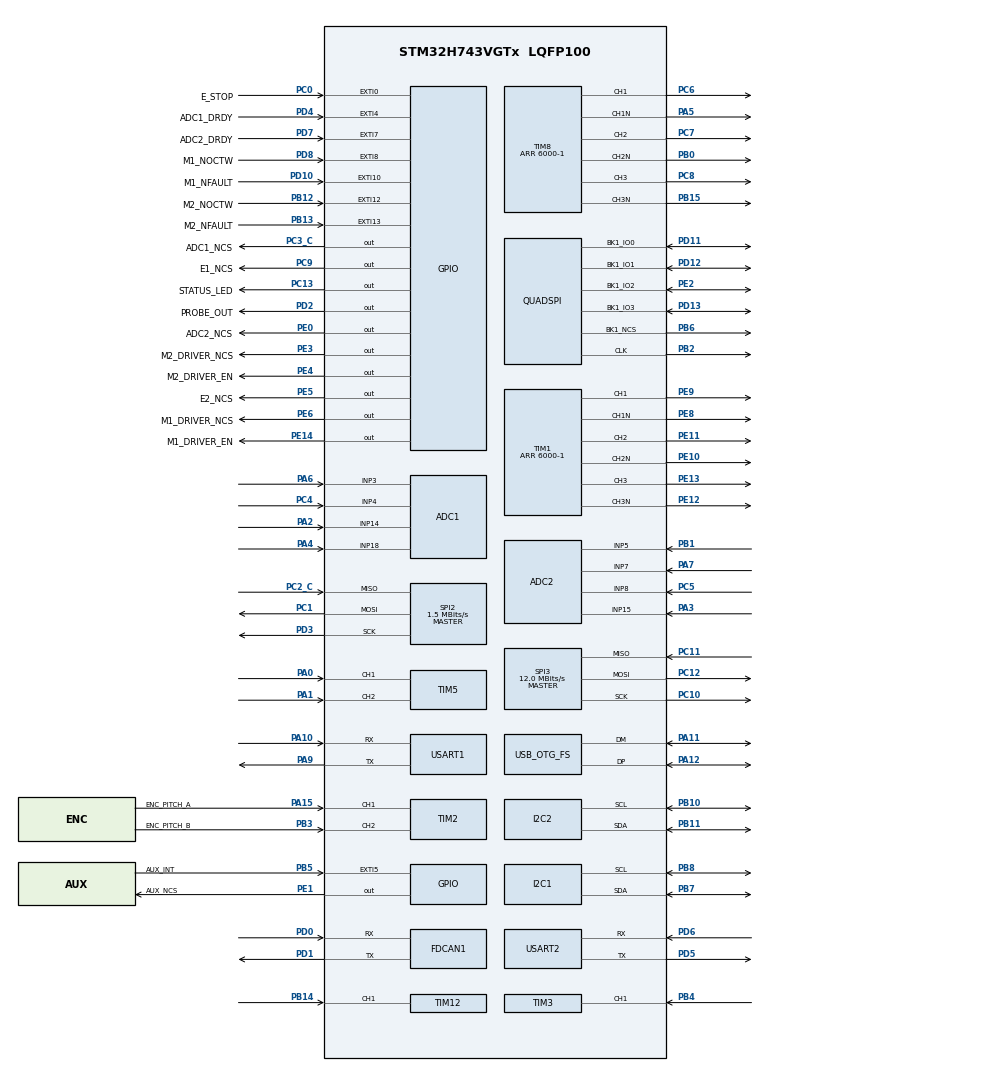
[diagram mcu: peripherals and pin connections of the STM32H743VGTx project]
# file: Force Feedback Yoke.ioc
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ADC1.AWD1HighThreshold=(65535-5000)*8
ADC1.AWD1ITMode=ENABLE
ADC1.AWD1LowThreshold=10000*8
ADC1.EOCSelection=ADC_EOC_SEQ_CONV
ADC1.EnableAnalogWatchDog1=true
ADC1.EnableInjectedConversion=ENABLE
ADC1.EnableInjectedOversampling=ENABLE
ADC1.EnableRegularConversion=DISABLE
ADC1.ExternalTrigInjecConv=ADC_EXTERNALTRIGINJEC_T8_TRGO
ADC1.InjNumberOfConversion=4
ADC1.InjOversamplingRatio=8
ADC1.InjOversamplingRightShift=ADC_RIGHTBITSHIFT_3
ADC1.InjectedChannel-10\#ChannelInjectedConversion=ADC_CHANNEL_18
ADC1.InjectedChannel-11\#ChannelInjectedConversion=ADC_CHANNEL_14
ADC1.InjectedChannel-12\#ChannelInjectedConversion=ADC_CHANNEL_4
ADC1.InjectedChannel-9\#ChannelInjectedConversion=ADC_CHANNEL_3
ADC1.InjectedOffsetNumber-10\#ChannelInjectedConversion=ADC_OFFSET_NONE
ADC1.InjectedOffsetNumber-11\#ChannelInjectedConversion=ADC_OFFSET_NONE
ADC1.InjectedOffsetNumber-12\#ChannelInjectedConversion=ADC_OFFSET_NONE
ADC1.InjectedOffsetNumber-9\#ChannelInjectedConversion=ADC_OFFSET_NONE
ADC1.InjectedOffsetSaturation-10\#ChannelInjectedConversion=DISABLE
ADC1.InjectedOffsetSaturation-11\#ChannelInjectedConversion=DISABLE
ADC1.InjectedOffsetSaturation-12\#ChannelInjectedConversion=DISABLE
ADC1.InjectedOffsetSaturation-9\#ChannelInjectedConversion=DISABLE
ADC1.InjectedOffsetSignedSaturation-10\#ChannelInjectedConversion=DISABLE
ADC1.InjectedOffsetSignedSaturation-11\#ChannelInjectedConversion=DISABLE
ADC1.InjectedOffsetSignedSaturation-12\#ChannelInjectedConversion=DISABLE
ADC1.InjectedOffsetSignedSaturation-9\#ChannelInjectedConversion=DISABLE
ADC1.InjectedRank-10\#ChannelInjectedConversion=2
ADC1.InjectedRank-11\#ChannelInjectedConversion=3
ADC1.InjectedRank-12\#ChannelInjectedConversion=4
ADC1.InjectedRank-9\#ChannelInjectedConversion=1
ADC1.InjectedSamplingTime-10\#ChannelInjectedConversion=ADC_SAMPLETIME_32CYCLES_5
ADC1.InjectedSamplingTime-11\#ChannelInjectedConversion=ADC_SAMPLETIME_32CYCLES_5
ADC1.InjectedSamplingTime-12\#ChannelInjectedConversion=ADC_SAMPLETIME_32CYCLES_5
ADC1.InjectedSamplingTime-9\#ChannelInjectedConversion=ADC_SAMPLETIME_32CYCLES_5
ADC1.OversamplingMode=DISABLE
ADC1.WatchdogMode=ADC_ANALOGWATCHDOG_ALL_INJEC
ADC1.injectedQueueMode=DISABLE
ADC1.master=1
ADC2.AWD1HighThreshold=(65535-5000)*8
ADC2.AWD1ITMode=ENABLE
ADC2.AWD1LowThreshold=10000*8
ADC2.ClockPrescaler=ADC_CLOCK_ASYNC_DIV1
ADC2.EOCSelection=ADC_EOC_SEQ_CONV
ADC2.EnableAnalogWatchDog1=true
ADC2.EnableAnalogWatchDog2=false
ADC2.EnableAnalogWatchDog3=false
ADC2.EnableInjectedConversion=ENABLE
ADC2.EnableInjectedOversampling=ENABLE
ADC2.EnableRegularConversion=DISABLE
ADC2.ExternalTrigInjecConv=ADC_EXTERNALTRIGINJEC_T1_TRGO
ADC2.InjNumberOfConversion=4
ADC2.InjOversamplingRatio=8
ADC2.InjOversamplingRightShift=ADC_RIGHTBITSHIFT_3
ADC2.InjectedChannel-13\#ChannelInjectedConversion=ADC_CHANNEL_7
ADC2.InjectedChannel-14\#ChannelInjectedConversion=ADC_CHANNEL_8
ADC2.InjectedChannel-15\#ChannelInjectedConversion=ADC_CHANNEL_5
ADC2.InjectedChannel-16\#ChannelInjectedConversion=ADC_CHANNEL_15
ADC2.InjectedOffsetNumber-13\#ChannelInjectedConversion=ADC_OFFSET_NONE
ADC2.InjectedOffsetNumber-14\#ChannelInjectedConversion=ADC_OFFSET_NONE
ADC2.InjectedOffsetNumber-15\#ChannelInjectedConversion=ADC_OFFSET_NONE
ADC2.InjectedOffsetNumber-16\#ChannelInjectedConversion=ADC_OFFSET_NONE
ADC2.InjectedOffsetSaturation-13\#ChannelInjectedConversion=DISABLE
ADC2.InjectedOffsetSaturation-14\#ChannelInjectedConversion=DISABLE
ADC2.InjectedOffsetSaturation-15\#ChannelInjectedConversion=DISABLE
ADC2.InjectedOffsetSaturation-16\#ChannelInjectedConversion=DISABLE
ADC2.InjectedOffsetSignedSaturation-13\#ChannelInjectedConversion=DISABLE
ADC2.InjectedOffsetSignedSaturation-14\#ChannelInjectedConversion=DISABLE
ADC2.InjectedOffsetSignedSaturation-15\#ChannelInjectedConversion=DISABLE
ADC2.InjectedOffsetSignedSaturation-16\#ChannelInjectedConversion=DISABLE
ADC2.InjectedRank-13\#ChannelInjectedConversion=1
ADC2.InjectedRank-14\#ChannelInjectedConversion=2
ADC2.InjectedRank-15\#ChannelInjectedConversion=3
ADC2.InjectedRank-16\#ChannelInjectedConversion=4
ADC2.InjectedSamplingTime-13\#ChannelInjectedConversion=ADC_SAMPLETIME_32CYCLES_5
ADC2.InjectedSamplingTime-14\#ChannelInjectedConversion=ADC_SAMPLETIME_32CYCLES_5
ADC2.InjectedSamplingTime-15\#ChannelInjectedConversion=ADC_SAMPLETIME_32CYCLES_5
ADC2.InjectedSamplingTime-16\#ChannelInjectedConversion=ADC_SAMPLETIME_32CYCLES_5
ADC2.Overrun=ADC_OVR_DATA_PRESERVED
ADC2.OversamplingMode=ENABLE
ADC2.Ratio=1
ADC2.WatchdogMode=ADC_ANALOGWATCHDOG_ALL_INJEC
ADC2.injectedQueueMode=DISABLE
CORTEX_M7.CPU_DCache=Disabled
CORTEX_M7.CPU_ICache=Enabled
CORTEX_M7.default_mode_Activation=1
CRC.CRCLength=CRC_POLYLENGTH_8B
CRC.DefaultInitValueUse=DEFAULT_INIT_VALUE_DISABLE
CRC.DefaultPolynomialUse=DEFAULT_POLYNOMIAL_DISABLE
Dma.Request0=USART2_RX
Dma.Request1=USART2_TX
Dma.Request10=TIM5_CH1
Dma.Request11=TIM5_CH2
Dma.Request2=SPI2_RX
Dma.Request3=SPI2_TX
Dma.Request4=USART1_RX
Dma.Request5=USART1_TX
Dma.Request6=SPI3_TX
Dma.Request7=SPI3_RX
Dma.Request8=TIM2_CH1
Dma.Request9=TIM2_CH2
Dma.SPI2_RX.2.Direction=DMA_PERIPH_TO_MEMORY
Dma.SPI2_RX.2.EventEnable=DISABLE
Dma.SPI2_RX.2.FIFOMode=DMA_FIFOMODE_DISABLE
Dma.SPI2_RX.2.Instance=DMA1_Stream0
Dma.SPI2_RX.2.MemDataAlignment=DMA_MDATAALIGN_BYTE
Dma.SPI2_RX.2.MemInc=DMA_MINC_ENABLE
Dma.SPI2_RX.2.Mode=DMA_NORMAL
Dma.SPI2_RX.2.PeriphDataAlignment=DMA_PDATAALIGN_BYTE
Dma.SPI2_RX.2.PeriphInc=DMA_PINC_DISABLE
Dma.SPI2_RX.2.Polarity=HAL_DMAMUX_REQ_GEN_RISING
Dma.SPI2_RX.2.Priority=DMA_PRIORITY_MEDIUM
Dma.SPI2_RX.2.RequestNumber=1
Dma.SPI2_RX.2.SignalID=NONE
Dma.SPI2_RX.2.SyncEnable=DISABLE
Dma.SPI2_RX.2.SyncPolarity=HAL_DMAMUX_SYNC_NO_EVENT
Dma.SPI2_RX.2.SyncRequestNumber=1
Dma.SPI2_RX.2.SyncSignalID=NONE
Dma.SPI2_TX.3.Direction=DMA_MEMORY_TO_PERIPH
Dma.SPI2_TX.3.EventEnable=DISABLE
Dma.SPI2_TX.3.FIFOMode=DMA_FIFOMODE_DISABLE
Dma.SPI2_TX.3.Instance=DMA1_Stream1
Dma.SPI2_TX.3.MemDataAlignment=DMA_MDATAALIGN_BYTE
Dma.SPI2_TX.3.MemInc=DMA_MINC_ENABLE
Dma.SPI2_TX.3.Mode=DMA_NORMAL
Dma.SPI2_TX.3.PeriphDataAlignment=DMA_PDATAALIGN_BYTE
Dma.SPI2_TX.3.PeriphInc=DMA_PINC_DISABLE
Dma.SPI2_TX.3.Polarity=HAL_DMAMUX_REQ_GEN_RISING
Dma.SPI2_TX.3.Priority=DMA_PRIORITY_MEDIUM
Dma.SPI2_TX.3.RequestNumber=1
Dma.SPI2_TX.3.SignalID=NONE
Dma.SPI2_TX.3.SyncEnable=DISABLE
Dma.SPI2_TX.3.SyncPolarity=HAL_DMAMUX_SYNC_NO_EVENT
Dma.SPI2_TX.3.SyncRequestNumber=1
Dma.SPI2_TX.3.SyncSignalID=NONE
Dma.SPI3_RX.7.Direction=DMA_PERIPH_TO_MEMORY
Dma.SPI3_RX.7.EventEnable=DISABLE
Dma.SPI3_RX.7.FIFOMode=DMA_FIFOMODE_DISABLE
Dma.SPI3_RX.7.Instance=DMA1_Stream7
Dma.SPI3_RX.7.MemDataAlignment=DMA_MDATAALIGN_BYTE
Dma.SPI3_RX.7.MemInc=DMA_MINC_ENABLE
Dma.SPI3_RX.7.Mode=DMA_NORMAL
Dma.SPI3_RX.7.PeriphDataAlignment=DMA_PDATAALIGN_BYTE
Dma.SPI3_RX.7.PeriphInc=DMA_PINC_DISABLE
Dma.SPI3_RX.7.Polarity=HAL_DMAMUX_REQ_GEN_RISING
Dma.SPI3_RX.7.Priority=DMA_PRIORITY_HIGH
Dma.SPI3_RX.7.RequestNumber=1
Dma.SPI3_RX.7.SignalID=NONE
Dma.SPI3_RX.7.SyncEnable=DISABLE
Dma.SPI3_RX.7.SyncPolarity=HAL_DMAMUX_SYNC_NO_EVENT
Dma.SPI3_RX.7.SyncRequestNumber=1
Dma.SPI3_RX.7.SyncSignalID=NONE
Dma.SPI3_TX.6.Direction=DMA_MEMORY_TO_PERIPH
Dma.SPI3_TX.6.EventEnable=DISABLE
Dma.SPI3_TX.6.FIFOMode=DMA_FIFOMODE_DISABLE
Dma.SPI3_TX.6.Instance=DMA1_Stream6
Dma.SPI3_TX.6.MemDataAlignment=DMA_MDATAALIGN_BYTE
Dma.SPI3_TX.6.MemInc=DMA_MINC_ENABLE
Dma.SPI3_TX.6.Mode=DMA_NORMAL
Dma.SPI3_TX.6.PeriphDataAlignment=DMA_PDATAALIGN_BYTE
Dma.SPI3_TX.6.PeriphInc=DMA_PINC_DISABLE
Dma.SPI3_TX.6.Polarity=HAL_DMAMUX_REQ_GEN_RISING
Dma.SPI3_TX.6.Priority=DMA_PRIORITY_HIGH
Dma.SPI3_TX.6.RequestNumber=1
Dma.SPI3_TX.6.SignalID=NONE
Dma.SPI3_TX.6.SyncEnable=DISABLE
Dma.SPI3_TX.6.SyncPolarity=HAL_DMAMUX_SYNC_NO_EVENT
Dma.SPI3_TX.6.SyncRequestNumber=1
Dma.SPI3_TX.6.SyncSignalID=NONE
Dma.TIM2_CH1.8.Direction=DMA_PERIPH_TO_MEMORY
Dma.TIM2_CH1.8.EventEnable=DISABLE
Dma.TIM2_CH1.8.FIFOMode=DMA_FIFOMODE_DISABLE
Dma.TIM2_CH1.8.Instance=DMA2_Stream0
Dma.TIM2_CH1.8.MemDataAlignment=DMA_MDATAALIGN_WORD
Dma.TIM2_CH1.8.MemInc=DMA_MINC_ENABLE
Dma.TIM2_CH1.8.Mode=DMA_CIRCULAR
Dma.TIM2_CH1.8.PeriphDataAlignment=DMA_PDATAALIGN_WORD
Dma.TIM2_CH1.8.PeriphInc=DMA_PINC_DISABLE
Dma.TIM2_CH1.8.Polarity=HAL_DMAMUX_REQ_GEN_RISING
Dma.TIM2_CH1.8.Priority=DMA_PRIORITY_MEDIUM
Dma.TIM2_CH1.8.RequestNumber=1
Dma.TIM2_CH1.8.SignalID=NONE
Dma.TIM2_CH1.8.SyncEnable=DISABLE
Dma.TIM2_CH1.8.SyncPolarity=HAL_DMAMUX_SYNC_NO_EVENT
Dma.TIM2_CH1.8.SyncRequestNumber=1
Dma.TIM2_CH1.8.SyncSignalID=NONE
Dma.TIM2_CH2.9.Direction=DMA_PERIPH_TO_MEMORY
Dma.TIM2_CH2.9.EventEnable=DISABLE
Dma.TIM2_CH2.9.FIFOMode=DMA_FIFOMODE_DISABLE
Dma.TIM2_CH2.9.Instance=DMA2_Stream1
Dma.TIM2_CH2.9.MemDataAlignment=DMA_MDATAALIGN_WORD
Dma.TIM2_CH2.9.MemInc=DMA_MINC_ENABLE
Dma.TIM2_CH2.9.Mode=DMA_CIRCULAR
Dma.TIM2_CH2.9.PeriphDataAlignment=DMA_PDATAALIGN_WORD
Dma.TIM2_CH2.9.PeriphInc=DMA_PINC_DISABLE
Dma.TIM2_CH2.9.Polarity=HAL_DMAMUX_REQ_GEN_RISING
Dma.TIM2_CH2.9.Priority=DMA_PRIORITY_MEDIUM
Dma.TIM2_CH2.9.RequestNumber=1
Dma.TIM2_CH2.9.SignalID=NONE
Dma.TIM2_CH2.9.SyncEnable=DISABLE
Dma.TIM2_CH2.9.SyncPolarity=HAL_DMAMUX_SYNC_NO_EVENT
Dma.TIM2_CH2.9.SyncRequestNumber=1
Dma.TIM2_CH2.9.SyncSignalID=NONE
Dma.TIM5_CH1.10.Direction=DMA_PERIPH_TO_MEMORY
Dma.TIM5_CH1.10.EventEnable=DISABLE
Dma.TIM5_CH1.10.FIFOMode=DMA_FIFOMODE_DISABLE
Dma.TIM5_CH1.10.Instance=DMA2_Stream2
Dma.TIM5_CH1.10.MemDataAlignment=DMA_MDATAALIGN_WORD
Dma.TIM5_CH1.10.MemInc=DMA_MINC_ENABLE
Dma.TIM5_CH1.10.Mode=DMA_NORMAL
Dma.TIM5_CH1.10.PeriphDataAlignment=DMA_PDATAALIGN_WORD
Dma.TIM5_CH1.10.PeriphInc=DMA_PINC_DISABLE
Dma.TIM5_CH1.10.Polarity=HAL_DMAMUX_REQ_GEN_RISING
Dma.TIM5_CH1.10.Priority=DMA_PRIORITY_MEDIUM
Dma.TIM5_CH1.10.RequestNumber=1
Dma.TIM5_CH1.10.SignalID=NONE
Dma.TIM5_CH1.10.SyncEnable=DISABLE
Dma.TIM5_CH1.10.SyncPolarity=HAL_DMAMUX_SYNC_NO_EVENT
Dma.TIM5_CH1.10.SyncRequestNumber=1
Dma.TIM5_CH1.10.SyncSignalID=NONE
Dma.TIM5_CH2.11.Direction=DMA_PERIPH_TO_MEMORY
Dma.TIM5_CH2.11.EventEnable=DISABLE
Dma.TIM5_CH2.11.FIFOMode=DMA_FIFOMODE_DISABLE
Dma.TIM5_CH2.11.Instance=DMA2_Stream3
Dma.TIM5_CH2.11.MemDataAlignment=DMA_MDATAALIGN_WORD
Dma.TIM5_CH2.11.MemInc=DMA_MINC_ENABLE
Dma.TIM5_CH2.11.Mode=DMA_NORMAL
Dma.TIM5_CH2.11.PeriphDataAlignment=DMA_PDATAALIGN_WORD
Dma.TIM5_CH2.11.PeriphInc=DMA_PINC_DISABLE
Dma.TIM5_CH2.11.Polarity=HAL_DMAMUX_REQ_GEN_RISING
Dma.TIM5_CH2.11.Priority=DMA_PRIORITY_MEDIUM
Dma.TIM5_CH2.11.RequestNumber=1
Dma.TIM5_CH2.11.SignalID=NONE
Dma.TIM5_CH2.11.SyncEnable=DISABLE
Dma.TIM5_CH2.11.SyncPolarity=HAL_DMAMUX_SYNC_NO_EVENT
Dma.TIM5_CH2.11.SyncRequestNumber=1
Dma.TIM5_CH2.11.SyncSignalID=NONE
Dma.USART1_RX.4.Direction=DMA_PERIPH_TO_MEMORY
Dma.USART1_RX.4.EventEnable=DISABLE
Dma.USART1_RX.4.FIFOMode=DMA_FIFOMODE_DISABLE
Dma.USART1_RX.4.Instance=DMA1_Stream4
Dma.USART1_RX.4.MemDataAlignment=DMA_MDATAALIGN_BYTE
Dma.USART1_RX.4.MemInc=DMA_MINC_ENABLE
Dma.USART1_RX.4.Mode=DMA_NORMAL
Dma.USART1_RX.4.PeriphDataAlignment=DMA_PDATAALIGN_BYTE
Dma.USART1_RX.4.PeriphInc=DMA_PINC_DISABLE
Dma.USART1_RX.4.Polarity=HAL_DMAMUX_REQ_GEN_RISING
Dma.USART1_RX.4.Priority=DMA_PRIORITY_LOW
Dma.USART1_RX.4.RequestNumber=1
Dma.USART1_RX.4.SignalID=NONE
Dma.USART1_RX.4.SyncEnable=DISABLE
Dma.USART1_RX.4.SyncPolarity=HAL_DMAMUX_SYNC_NO_EVENT
Dma.USART1_RX.4.SyncRequestNumber=1
Dma.USART1_RX.4.SyncSignalID=NONE
Dma.USART1_TX.5.Direction=DMA_MEMORY_TO_PERIPH
Dma.USART1_TX.5.EventEnable=DISABLE
Dma.USART1_TX.5.FIFOMode=DMA_FIFOMODE_DISABLE
Dma.USART1_TX.5.Instance=DMA1_Stream5
Dma.USART1_TX.5.MemDataAlignment=DMA_MDATAALIGN_BYTE
Dma.USART1_TX.5.MemInc=DMA_MINC_ENABLE
Dma.USART1_TX.5.Mode=DMA_NORMAL
Dma.USART1_TX.5.PeriphDataAlignment=DMA_PDATAALIGN_BYTE
Dma.USART1_TX.5.PeriphInc=DMA_PINC_DISABLE
Dma.USART1_TX.5.Polarity=HAL_DMAMUX_REQ_GEN_RISING
Dma.USART1_TX.5.Priority=DMA_PRIORITY_LOW
Dma.USART1_TX.5.RequestNumber=1
Dma.USART1_TX.5.SignalID=NONE
Dma.USART1_TX.5.SyncEnable=DISABLE
Dma.USART1_TX.5.SyncPolarity=HAL_DMAMUX_SYNC_NO_EVENT
Dma.USART1_TX.5.SyncRequestNumber=1
Dma.USART1_TX.5.SyncSignalID=NONE
Dma.USART2_RX.0.Direction=DMA_PERIPH_TO_MEMORY
Dma.USART2_RX.0.EventEnable=DISABLE
Dma.USART2_RX.0.FIFOMode=DMA_FIFOMODE_DISABLE
Dma.USART2_RX.0.Instance=DMA1_Stream2
Dma.USART2_RX.0.MemDataAlignment=DMA_MDATAALIGN_BYTE
Dma.USART2_RX.0.MemInc=DMA_MINC_ENABLE
Dma.USART2_RX.0.Mode=DMA_NORMAL
Dma.USART2_RX.0.PeriphDataAlignment=DMA_PDATAALIGN_BYTE
Dma.USART2_RX.0.PeriphInc=DMA_PINC_DISABLE
Dma.USART2_RX.0.Polarity=HAL_DMAMUX_REQ_GEN_RISING
Dma.USART2_RX.0.Priority=DMA_PRIORITY_LOW
Dma.USART2_RX.0.RequestNumber=1
Dma.USART2_RX.0.SignalID=NONE
Dma.USART2_RX.0.SyncEnable=DISABLE
Dma.USART2_RX.0.SyncPolarity=HAL_DMAMUX_SYNC_NO_EVENT
Dma.USART2_RX.0.SyncRequestNumber=1
Dma.USART2_RX.0.SyncSignalID=NONE
Dma.USART2_TX.1.Direction=DMA_MEMORY_TO_PERIPH
Dma.USART2_TX.1.EventEnable=DISABLE
Dma.USART2_TX.1.FIFOMode=DMA_FIFOMODE_DISABLE
Dma.USART2_TX.1.Instance=DMA1_Stream3
Dma.USART2_TX.1.MemDataAlignment=DMA_MDATAALIGN_BYTE
Dma.USART2_TX.1.MemInc=DMA_MINC_ENABLE
Dma.USART2_TX.1.Mode=DMA_NORMAL
Dma.USART2_TX.1.PeriphDataAlignment=DMA_PDATAALIGN_BYTE
Dma.USART2_TX.1.PeriphInc=DMA_PINC_DISABLE
Dma.USART2_TX.1.Polarity=HAL_DMAMUX_REQ_GEN_RISING
Dma.USART2_TX.1.Priority=DMA_PRIORITY_LOW
Dma.USART2_TX.1.RequestNumber=1
Dma.USART2_TX.1.SignalID=NONE
Dma.USART2_TX.1.SyncEnable=DISABLE
Dma.USART2_TX.1.SyncPolarity=HAL_DMAMUX_SYNC_NO_EVENT
Dma.USART2_TX.1.SyncRequestNumber=1
Dma.USART2_TX.1.SyncSignalID=NONE
FDCAN1.CalculateBaudRateNominal=1666666
FDCAN1.CalculateTimeBitNominal=600
FDCAN1.CalculateTimeQuantumNominal=200.0
I2C1.Timing=0x307075B1
I2C2.CustomTiming=Disabled
I2C2.Timing=0x307075B1
Mcu.Family=STM32H7
Mcu.Name=STM32H743VGTx
Mcu.Package=LQFP100
NVIC.ADC_IRQn=true\:1\:0\:true\:false\:true\:true\:true\:true
NVIC.DMA1_Stream0_IRQn=true\:1\:0\:true\:false\:true\:false\:true\:true
NVIC.DMA1_Stream1_IRQn=true\:1\:0\:true\:false\:true\:false\:true\:true
NVIC.DMA1_Stream2_IRQn=true\:3\:0\:true\:false\:true\:false\:true\:true
NVIC.DMA1_Stream3_IRQn=true\:3\:0\:true\:false\:true\:false\:true\:true
NVIC.DMA1_Stream4_IRQn=true\:3\:0\:true\:false\:true\:false\:true\:true
NVIC.DMA1_Stream5_IRQn=true\:3\:0\:true\:false\:true\:false\:true\:true
NVIC.DMA1_Stream6_IRQn=true\:0\:0\:false\:false\:true\:false\:true\:true
NVIC.DMA1_Stream7_IRQn=true\:0\:0\:false\:false\:true\:false\:true\:true
NVIC.DMA2_Stream0_IRQn=true\:0\:0\:false\:false\:true\:false\:true\:true
NVIC.DMA2_Stream1_IRQn=true\:0\:0\:false\:false\:true\:false\:true\:true
NVIC.DMA2_Stream2_IRQn=true\:0\:0\:false\:false\:true\:false\:true\:true
NVIC.DMA2_Stream3_IRQn=true\:0\:0\:false\:false\:true\:false\:true\:true
NVIC.EXTI0_IRQn=true\:0\:0\:false\:false\:true\:true\:true\:true
NVIC.EXTI4_IRQn=true\:1\:0\:true\:false\:true\:true\:true\:true
NVIC.OTG_FS_IRQn=true\:0\:0\:false\:false\:true\:true\:true\:true
NVIC.PriorityGroup=NVIC_PRIORITYGROUP_4
NVIC.SPI2_IRQn=true\:2\:0\:true\:false\:true\:false\:true\:true
NVIC.SPI3_IRQn=true\:0\:0\:false\:false\:true\:false\:true\:true
NVIC.TIM2_IRQn=true\:0\:0\:false\:false\:true\:true\:true\:true
NVIC.TIM5_IRQn=true\:0\:0\:false\:false\:true\:true\:true\:true
NVIC.TIM7_IRQn=true\:3\:0\:true\:false\:true\:true\:true\:true
NVIC.TIM8_BRK_TIM12_IRQn=true\:0\:0\:false\:false\:true\:true\:true\:true
NVIC.USART1_IRQn=true\:4\:0\:true\:false\:true\:true\:true\:true
NVIC.USART2_IRQn=true\:4\:0\:true\:false\:true\:true\:true\:true
PA0.Signal=S_TIM5_CH1
PA1.Signal=S_TIM5_CH2
PA10.Mode=Asynchronous
PA10.Signal=USART1_RX
PA11.Mode=Device_Only
PA11.Signal=USB_OTG_FS_DM
PA12.Mode=Device_Only
PA12.Signal=USB_OTG_FS_DP
PA13\ (JTMS/SWDIO).Mode=Serial_Wire
PA13\ (JTMS/SWDIO).Signal=DEBUG_JTMS-SWDIO
PA14\ (JTCK/SWCLK).Mode=Serial_Wire
PA14\ (JTCK/SWCLK).Signal=DEBUG_JTCK-SWCLK
PA15\ (JTDI).GPIO_Label=ENC_PITCH_A
PA15\ (JTDI).Signal=S_TIM2_CH1_ETR
PA2.Signal=ADCx_INP14
PA3.Signal=ADCx_INP15
PA4.Signal=ADCx_INP18
PA5.Mode=PWM Generation1 CH1 CH1N
PA5.Signal=TIM8_CH1N
PA6.Signal=ADCx_INP3
PA7.Signal=ADCx_INP7
PA9.Mode=Asynchronous
PA9.Signal=USART1_TX
PB0.Mode=PWM Generation2 CH2 CH2N
PB0.Signal=TIM8_CH2N
PB1.Signal=ADCx_INP5
PB10.Mode=I2C
PB10.Signal=I2C2_SCL
PB11.Mode=I2C
PB11.Signal=I2C2_SDA
PB12.GPIO_Label=M2_NOCTW
PB12.Signal=GPXTI12
PB13.GPIO_Label=M2_NFAULT
PB13.Signal=GPXTI13
PB14.Signal=S_TIM12_CH1
PB15.Mode=PWM Generation3 CH3 CH3N
PB15.Signal=TIM8_CH3N
PB2.Mode=Single Bank 1
PB2.Signal=QUADSPI_CLK
PB3\ (JTDO/TRACESWO).GPIO_Label=ENC_PITCH_B
PB3\ (JTDO/TRACESWO).Signal=S_TIM2_CH2
PB4\ (NJTRST).Signal=S_TIM3_CH1
PB5.GPIO_Label=AUX_INT
PB5.Signal=GPXTI5
PB6.Mode=Single Bank 1
PB6.PinAttribute=Free
PB6.Signal=QUADSPI_BK1_NCS
PB7.Mode=I2C
PB7.PinAttribute=Free
PB7.Signal=I2C1_SDA
PB8.Mode=I2C
PB8.PinAttribute=Free
PB8.Signal=I2C1_SCL
PC0.GPIO_Label=E_STOP
PC0.GPIO_ModeDefaultEXTI=GPIO_MODE_IT_RISING_FALLING
PC0.GPIO_PuPd=GPIO_PULLUP
PC0.Signal=GPXTI0
PC1.Mode=Full_Duplex_Master
PC1.Signal=SPI2_MOSI
PC10.Mode=Full_Duplex_Master
PC10.Signal=SPI3_SCK
PC11.GPIO_Speed=GPIO_SPEED_FREQ_LOW
PC11.Mode=Full_Duplex_Master
PC11.Signal=SPI3_MISO
PC12.GPIO_Speed=GPIO_SPEED_FREQ_LOW
PC12.Mode=Full_Duplex_Master
PC12.Signal=SPI3_MOSI
PC13.GPIO_Label=STATUS_LED
PC13.Signal=GPIO_Output
PC14-OSC32_IN\ (OSC32_IN).Mode=LSE-External-Oscillator
PC14-OSC32_IN\ (OSC32_IN).Signal=RCC_OSC32_IN
PC15-OSC32_OUT\ (OSC32_OUT).Mode=LSE-External-Oscillator
PC15-OSC32_OUT\ (OSC32_OUT).Signal=RCC_OSC32_OUT
PC2_C.Mode=Full_Duplex_Master
PC2_C.Signal=SPI2_MISO
PC3_C.GPIO_Label=ADC1_NCS
PC3_C.PinState=GPIO_PIN_SET
PC3_C.Signal=GPIO_Output
PC4.Signal=ADCx_INP4
PC5.Signal=ADCx_INP8
PC6.Signal=S_TIM8_CH1
PC7.Signal=S_TIM8_CH2
PC8.Signal=S_TIM8_CH3
PC9.GPIO_Label=E1_NCS
PC9.PinState=GPIO_PIN_SET
PC9.Signal=GPIO_Output
PD0.Mode=FDCAN_Activate
PD0.Signal=FDCAN1_RX
PD1.Mode=FDCAN_Activate
PD1.Signal=FDCAN1_TX
PD10.GPIO_Label=M1_NFAULT
PD10.Signal=GPXTI10
PD11.Mode=Single Bank 1
PD11.Signal=QUADSPI_BK1_IO0
PD12.Mode=Single Bank 1
PD12.Signal=QUADSPI_BK1_IO1
PD13.Mode=Single Bank 1
PD13.Signal=QUADSPI_BK1_IO3
PD2.GPIO_Label=PROBE_OUT
PD2.GPIO_Speed=GPIO_SPEED_FREQ_MEDIUM
PD2.Signal=GPIO_Output
PD3.Mode=Full_Duplex_Master
PD3.Signal=SPI2_SCK
PD4.GPIO_Label=ADC1_DRDY
PD4.GPIO_ModeDefaultEXTI=GPIO_MODE_IT_RISING
PD4.Signal=GPXTI4
PD5.Mode=Asynchronous
PD5.Signal=USART2_TX
PD6.Mode=Asynchronous
PD6.Signal=USART2_RX
PD7.GPIO_Label=ADC2_DRDY
PD7.Signal=GPXTI7
PD8.GPIO_Label=M1_NOCTW
PD8.Signal=GPXTI8
PE0.GPIO_Label=ADC2_NCS
PE0.PinAttribute=Free
PE0.PinState=GPIO_PIN_SET
PE0.Signal=GPIO_Output
PE1.GPIO_Label=AUX_NCS
PE1.PinAttribute=Free
PE1.PinState=GPIO_PIN_SET
PE1.Signal=GPIO_Output
PE10.Mode=PWM Generation2 CH2 CH2N
PE10.Signal=TIM1_CH2N
PE11.Signal=S_TIM1_CH2
PE12.Mode=PWM Generation3 CH3 CH3N
PE12.Signal=TIM1_CH3N
PE13.Signal=S_TIM1_CH3
PE14.GPIO_Label=M1_DRIVER_EN
PE14.Signal=GPIO_Output
PE2.Mode=Single Bank 1
PE2.PinAttribute=Free
PE2.Signal=QUADSPI_BK1_IO2
PE3.GPIO_Label=M2_DRIVER_NCS
PE3.PinAttribute=Free
PE3.PinState=GPIO_PIN_SET
PE3.Signal=GPIO_Output
PE4.GPIO_Label=M2_DRIVER_EN
PE4.PinAttribute=Free
PE4.Signal=GPIO_Output
PE5.GPIO_Label=E2_NCS
PE5.PinAttribute=Free
PE5.PinState=GPIO_PIN_SET
PE5.Signal=GPIO_Output
PE6.GPIO_Label=M1_DRIVER_NCS
PE6.PinAttribute=Free
PE6.PinState=GPIO_PIN_SET
PE6.Signal=GPIO_Output
PE8.Mode=PWM Generation1 CH1 CH1N
PE8.Signal=TIM1_CH1N
PE9.Signal=S_TIM1_CH1
PH0-OSC_IN\ (PH0).Mode=HSE-External-Oscillator
PH0-OSC_IN\ (PH0).Signal=RCC_OSC_IN
PH1-OSC_OUT\ (PH1).Mode=HSE-External-Oscillator
PH1-OSC_OUT\ (PH1).Signal=RCC_OSC_OUT
ProjectManager.HeapSize=0x200
ProjectManager.StackSize=0x400
ProjectManager.TargetToolchain=STM32CubeIDE
RCC.ADCFreq_Value=80000000
RCC.APB1Freq_Value=120000000
RCC.APB2Freq_Value=120000000
RCC.APB3Freq_Value=120000000
RCC.APB4Freq_Value=120000000
RCC.CortexFreq_Value=480000000
RCC.D1PPRE=RCC_APB3_DIV2
RCC.D2PPRE1=RCC_APB1_DIV2
RCC.D2PPRE2=RCC_APB2_DIV2
RCC.D3PPRE=RCC_APB4_DIV2
RCC.DIVM1=4
RCC.DIVM2=4
RCC.DIVN1=60
RCC.DIVN2=10
RCC.DIVQ1=5
RCC.FDCANCLockSelection=RCC_FDCANCLKSOURCE_PLL2
RCC.HCLKFreq_Value=240000000
RCC.HPRE=RCC_HCLK_DIV2
RCC.PLL1_VCI_Range-AdvancedSettings=RCC_PLL1VCIRANGE_0
RCC.PLL1_VCO_SEL-AdvancedSettings=RCC_PLL1VCOMEDIUM
RCC.PLL2FRACN=0
RCC.PLL2_VCI_Range-AdvancedSettings=RCC_PLL2VCIRANGE_0
RCC.PLL3FRACN=0
RCC.PLLFRACN=0
RCC.SYSCLKFreq_VALUE=480000000
RCC.SYSCLKSource=RCC_SYSCLKSOURCE_PLLCLK
RCC.USBCLockSelection=RCC_USBCLKSOURCE_HSI48
RCC.USBFreq_Value=48000000
SH.ADCx_INP14.0=ADC1_INP14,IN14-Single-Ended
SH.ADCx_INP15.0=ADC2_INP15,IN15-Single-Ended
SH.ADCx_INP18.0=ADC1_INP18,IN18-Single-Ended
SH.ADCx_INP3.0=ADC1_INP3,IN3-Single-Ended
SH.ADCx_INP4.0=ADC1_INP4,IN4-Single-Ended
SH.ADCx_INP5.0=ADC2_INP5,IN5-Single-Ended
SH.ADCx_INP7.0=ADC2_INP7,IN7-Single-Ended
SH.ADCx_INP8.0=ADC2_INP8,IN8-Single-Ended
SH.S_TIM12_CH1.0=TIM12_CH1,Input_Capture1_from_TI1
SH.S_TIM1_CH1.0=TIM1_CH1,PWM Generation1 CH1 CH1N
SH.S_TIM1_CH2.0=TIM1_CH2,PWM Generation2 CH2 CH2N
SH.S_TIM1_CH3.0=TIM1_CH3,PWM Generation3 CH3 CH3N
SH.S_TIM2_CH1_ETR.0=TIM2_CH1,Input_Capture1_from_TI1
SH.S_TIM2_CH2.0=TIM2_CH2,Input_Capture2_from_TI2
SH.S_TIM3_CH1.0=TIM3_CH1,Input_Capture1_from_TI1
SH.S_TIM5_CH1.0=TIM5_CH1,Input_Capture1_from_TI1
SH.S_TIM5_CH2.0=TIM5_CH2,Input_Capture2_from_TI2
SH.S_TIM8_CH1.0=TIM8_CH1,PWM Generation1 CH1 CH1N
SH.S_TIM8_CH2.0=TIM8_CH2,PWM Generation2 CH2 CH2N
SH.S_TIM8_CH3.0=TIM8_CH3,PWM Generation3 CH3 CH3N
SPI2.BaudRatePrescaler=SPI_BAUDRATEPRESCALER_128
SPI2.CLKPhase=SPI_PHASE_2EDGE
SPI2.CalculateBaudRate=1.5 MBits/s
SPI2.DataSize=SPI_DATASIZE_8BIT
SPI2.Direction=SPI_DIRECTION_2LINES
SPI2.MasterReceiverAutoSusp=SPI_MASTER_RX_AUTOSUSP_DISABLE
SPI2.Mode=SPI_MODE_MASTER
SPI2.NSSPMode=SPI_NSS_PULSE_ENABLE
SPI2.VirtualType=VM_MASTER
SPI3.BaudRatePrescaler=SPI_BAUDRATEPRESCALER_16
SPI3.CLKPhase=SPI_PHASE_2EDGE
SPI3.CLKPolarity=SPI_POLARITY_HIGH
SPI3.CRCCalculation=SPI_CRCCALCULATION_DISABLE
SPI3.CalculateBaudRate=12.0 MBits/s
SPI3.DataSize=SPI_DATASIZE_8BIT
SPI3.Direction=SPI_DIRECTION_2LINES
SPI3.MasterSSIdleness=SPI_MASTER_SS_IDLENESS_02CYCLE
SPI3.Mode=SPI_MODE_MASTER
SPI3.NSSPMode=SPI_NSS_PULSE_ENABLE
SPI3.VirtualType=VM_MASTER
TIM1.AutoReloadPreload=TIM_AUTORELOAD_PRELOAD_ENABLE
TIM1.Channel-Output\ Compare4\ No\ Output=TIM_CHANNEL_4
TIM1.Channel-PWM\ Generation1\ CH1\ CH1N=TIM_CHANNEL_1
TIM1.Channel-PWM\ Generation2\ CH2\ CH2N=TIM_CHANNEL_2
TIM1.Channel-PWM\ Generation3\ CH3\ CH3N=TIM_CHANNEL_3
TIM1.CounterMode=TIM_COUNTERMODE_CENTERALIGNED1
TIM1.DeadTime=40
TIM1.OC4Preload=DISABLE
TIM1.OCMode_4=TIM_OCMODE_TOGGLE
TIM1.OffStateIDLEMode=TIM_OSSI_ENABLE
TIM1.OffStateRunMode=TIM_OSSR_ENABLE
TIM1.Period=6000-1
TIM1.Pulse-Output\ Compare4\ No\ Output=1
TIM1.Pulse-PWM\ Generation1\ CH1\ CH1N=3000-1
TIM1.Pulse-PWM\ Generation2\ CH2\ CH2N=3000-1
TIM1.Pulse-PWM\ Generation3\ CH3\ CH3N=3000-1
TIM1.TIM_MasterOutputTrigger=TIM_TRGO_OC4REF
TIM1.TIM_MasterOutputTrigger2=TIM_TRGO2_RESET
TIM12.Channel-Input_Capture1_from_TI1=TIM_CHANNEL_1
TIM12.Prescaler=240-1
TIM2.Channel-Input_Capture1_from_TI1=TIM_CHANNEL_1
TIM2.Channel-Input_Capture2_from_TI2=TIM_CHANNEL_2
TIM2.ICFilter_CH1=0
TIM2.ICFilter_CH2=0
TIM2.ICPolarity_CH1=TIM_INPUTCHANNELPOLARITY_BOTHEDGE
TIM2.ICPolarity_CH2=TIM_INPUTCHANNELPOLARITY_BOTHEDGE
TIM2.TIM_MasterOutputTrigger=TIM_TRGO_RESET
TIM3.Channel-Input_Capture1_from_TI1=TIM_CHANNEL_1
TIM3.Prescaler=240-1
TIM3.TIM_MasterOutputTrigger=TIM_TRGO_UPDATE
TIM4.Channel-Output\ Compare1\ No\ Output=TIM_CHANNEL_1
TIM4.ClockDivision=TIM_CLOCKDIVISION_DIV4
TIM4.OCMode_1=TIM_OCMODE_ACTIVE
TIM4.Prescaler=65535
TIM4.Pulse-Output\ Compare1\ No\ Output=2
TIM4.TIM_MasterOutputTrigger=TIM_TRGO_OC1REF
TIM5.Channel-Input_Capture1_from_TI1=TIM_CHANNEL_1
TIM5.Channel-Input_Capture2_from_TI2=TIM_CHANNEL_2
TIM5.ICFilter_CH1=5
TIM5.ICFilter_CH2=5
TIM5.ICPolarity_CH1=TIM_INPUTCHANNELPOLARITY_BOTHEDGE
TIM5.ICPolarity_CH2=TIM_INPUTCHANNELPOLARITY_BOTHEDGE
TIM5.TIM_MasterOutputTrigger=TIM_TRGO_RESET
TIM6.AutoReloadPreload=TIM_AUTORELOAD_PRELOAD_ENABLE
TIM6.Prescaler=240-1
TIM7.AutoReloadPreload=TIM_AUTORELOAD_PRELOAD_ENABLE
TIM7.Period=1000-1
TIM7.Prescaler=240-1
TIM8.AutoReloadPreload=TIM_AUTORELOAD_PRELOAD_ENABLE
TIM8.Channel-Output\ Compare4\ No\ Output=TIM_CHANNEL_4
TIM8.Channel-PWM\ Generation1\ CH1\ CH1N=TIM_CHANNEL_1
TIM8.Channel-PWM\ Generation2\ CH2\ CH2N=TIM_CHANNEL_2
TIM8.Channel-PWM\ Generation3\ CH3\ CH3N=TIM_CHANNEL_3
TIM8.CounterMode=TIM_COUNTERMODE_CENTERALIGNED1
TIM8.DeadTime=40
TIM8.OCMode_4=TIM_OCMODE_TOGGLE
TIM8.OffStateIDLEMode=TIM_OSSI_ENABLE
TIM8.OffStateRunMode=TIM_OSSR_ENABLE
TIM8.Period=6000-1
TIM8.Pulse-Output\ Compare4\ No\ Output=1
TIM8.Pulse-PWM\ Generation1\ CH1\ CH1N=3000-1
TIM8.Pulse-PWM\ Generation2\ CH2\ CH2N=3000-1
TIM8.Pulse-PWM\ Generation3\ CH3\ CH3N=3000-1
TIM8.TIM_MasterOutputTrigger=TIM_TRGO_OC4REF
USART1.VirtualMode-Asynchronous=VM_ASYNC
USART2.VirtualMode-Asynchronous=VM_ASYNC
USB_DEVICE.CLASS_NAME_FS=CDC
USB_DEVICE.VirtualMode-CDC_FS=Cdc
USB_DEVICE.VirtualModeFS=Cdc_FS
USB_OTG_FS.VirtualMode=Device_Only
VP_CRC_VS_CRC.Mode=CRC_Activate
VP_MEMORYMAP_VS_MEMORYMAP.Mode=CurAppReg
VP_TIM12_VS_ClockSourceINT.Mode=Internal
VP_TIM12_VS_ClockSourceITR.Mode=TriggerSource_ITR0
VP_TIM12_VS_ControllerModeTrigger.Mode=Trigger Mode
VP_TIM1_VS_ClockSourceINT.Mode=Internal
VP_TIM1_VS_no_output4.Mode=Output Compare4 No Output
VP_TIM2_VS_ClockSourceINT.Mode=Internal
VP_TIM3_VS_ClockSourceINT.Mode=Internal
VP_TIM3_VS_ClockSourceITR.Mode=TriggerSource_ITR3
VP_TIM3_VS_ControllerModeTrigger.Mode=Trigger Mode
VP_TIM4_VS_ClockSourceINT.Mode=Internal
VP_TIM4_VS_OPM.Mode=OPM_bit
VP_TIM4_VS_no_output1.Mode=Output Compare1 No Output
VP_TIM5_VS_ClockSourceINT.Mode=Internal
VP_TIM6_VS_ClockSourceINT.Mode=Enable_Timer
VP_TIM7_VS_ClockSourceINT.Mode=Enable_Timer
VP_TIM8_VS_ClockSourceINT.Mode=Internal
VP_TIM8_VS_no_output4.Mode=Output Compare4 No Output
VP_USB_DEVICE_VS_USB_DEVICE_CDC_FS.Mode=CDC_FS
board=custom

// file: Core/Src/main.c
/* USER CODE BEGIN Header */
/**
  ******************************************************************************
  * @file           : main.c
  * @brief          : Main program body
  ******************************************************************************
  * @attention
  *
  * Copyright (c) 2025 STMicroelectronics.
  * All rights reserved.
  *
  * This software is licensed under terms that can be found in the LICENSE file
  * in the root directory of this software component.
  * If no LICENSE file comes with this software, it is provided AS-IS.
  *
  ******************************************************************************
  */
/* USER CODE END Header */
#include "main.h"
#include "usb_device.h"

/* USER CODE BEGIN Includes */
#include "bsp.h"
#include "bsp_it.h"
#include "app.h"
/* USER CODE END Includes */

ADC_HandleTypeDef hadc1;
ADC_HandleTypeDef hadc2;

CRC_HandleTypeDef hcrc;

FDCAN_HandleTypeDef hfdcan1;

I2C_HandleTypeDef hi2c1;
I2C_HandleTypeDef hi2c2;

QSPI_HandleTypeDef hqspi;

SPI_HandleTypeDef hspi2;
SPI_HandleTypeDef hspi3;
DMA_HandleTypeDef hdma_spi2_rx;
DMA_HandleTypeDef hdma_spi2_tx;
DMA_HandleTypeDef hdma_spi3_tx;
DMA_HandleTypeDef hdma_spi3_rx;

TIM_HandleTypeDef htim1;
TIM_HandleTypeDef htim2;
TIM_HandleTypeDef htim3;
TIM_HandleTypeDef htim4;
TIM_HandleTypeDef htim5;
TIM_HandleTypeDef htim6;
TIM_HandleTypeDef htim7;
TIM_HandleTypeDef htim8;
TIM_HandleTypeDef htim12;
DMA_HandleTypeDef hdma_tim2_ch1;
DMA_HandleTypeDef hdma_tim2_ch2;
DMA_HandleTypeDef hdma_tim5_ch1;
DMA_HandleTypeDef hdma_tim5_ch2;

UART_HandleTypeDef huart1;
UART_HandleTypeDef huart2;
DMA_HandleTypeDef hdma_usart1_rx;
DMA_HandleTypeDef hdma_usart1_tx;
DMA_HandleTypeDef hdma_usart2_rx;
DMA_HandleTypeDef hdma_usart2_tx;

void SystemClock_Config(void);
void PeriphCommonClock_Config(void);
static void MPU_Config(void);
static void MX_GPIO_Init(void);
static void MX_DMA_Init(void);
static void MX_TIM1_Init(void);
static void MX_ADC1_Init(void);
static void MX_ADC2_Init(void);
static void MX_TIM8_Init(void);
static void MX_I2C1_Init(void);
static void MX_I2C2_Init(void);
static void MX_USART2_UART_Init(void);
static void MX_SPI2_Init(void);
static void MX_FDCAN1_Init(void);
static void MX_TIM2_Init(void);
static void MX_TIM5_Init(void);
static void MX_QUADSPI_Init(void);
static void MX_SPI3_Init(void);
static void MX_USART1_UART_Init(void);
static void MX_TIM6_Init(void);
static void MX_TIM7_Init(void);
static void MX_TIM12_Init(void);
static void MX_TIM3_Init(void);
static void MX_TIM4_Init(void);
static void MX_CRC_Init(void);

/* USER CODE BEGIN 0 */
void HAL_GPIO_EXTI_Callback(uint16_t GPIO_Pin) {
	BspIT_EXTIIT(GPIO_Pin);
}

void HAL_TIM_PeriodElapsedCallback(TIM_HandleTypeDef *htim) {
	BspIT_TimIT(htim);
}

void HAL_TIM_OC_DelayElapsedCallback(TIM_HandleTypeDef *htim) {
//	GPIOSetState(&probeGpio, !GPIOGetState(&probeGpio));
}

void HAL_ADCEx_InjectedConvCpltCallback(ADC_HandleTypeDef *hadc) {
	BspIT_ADCIT(hadc);
}

void HAL_ADC_LevelOutOfWindowCallback(ADC_HandleTypeDef* hadc) {
	BspIT_ADCWatchDogIT(hadc);
}

void HAL_SPI_TxRxCpltCallback(SPI_HandleTypeDef *hspi) {
	BspIT_SPIIT(hspi);
}

void HAL_UART_TxCpltCallback(UART_HandleTypeDef *huart) {
	BspIT_UARTTxCpltIT(huart);
}

void HAL_UART_RxCpltCallback(UART_HandleTypeDef *huart) {
	BspIT_UARTRxCpltIT(huart);
}

/* USER CODE END 0 */

int main(void)
{

  /* MPU Configuration--------------------------------------------------------*/
  MPU_Config();

  /* Enable the CPU Cache */

  /* Enable I-Cache---------------------------------------------------------*/
  SCB_EnableICache();

  /* MCU Configuration--------------------------------------------------------*/

  /* Reset of all peripherals, Initializes the Flash interface and the Systick. */
  HAL_Init();

  /* Configure the system clock */
  SystemClock_Config();

  /* Configure the peripherals common clocks */
  PeriphCommonClock_Config();

  /* Initialize all configured peripherals */
  MX_GPIO_Init();
  MX_DMA_Init();
  MX_TIM1_Init();
  MX_ADC1_Init();
  MX_ADC2_Init();
  MX_TIM8_Init();
  MX_I2C1_Init();
  MX_I2C2_Init();
  MX_USART2_UART_Init();
  MX_SPI2_Init();
  MX_FDCAN1_Init();
  MX_TIM2_Init();
  MX_TIM5_Init();
  MX_QUADSPI_Init();
  MX_SPI3_Init();
  MX_USART1_UART_Init();
  MX_TIM6_Init();
  MX_TIM7_Init();
  MX_TIM12_Init();
  MX_TIM3_Init();
  MX_USB_DEVICE_Init();
  MX_TIM4_Init();
  MX_CRC_Init();
  /* USER CODE BEGIN 2 */
  Bsp_Init();
  Application_Init();
  Application_Run();
  /* USER CODE END 2 */

  /* Infinite loop */
  while (1)
  {

  }
}

void SystemClock_Config(void)
{
  RCC_OscInitTypeDef RCC_OscInitStruct = {0};
  RCC_ClkInitTypeDef RCC_ClkInitStruct = {0};

  /** Supply configuration update enable
  */
  HAL_PWREx_ConfigSupply(PWR_LDO_SUPPLY);

  /** Configure the main internal regulator output voltage
  */
  __HAL_PWR_VOLTAGESCALING_CONFIG(PWR_REGULATOR_VOLTAGE_SCALE0);

  while(!__HAL_PWR_GET_FLAG(PWR_FLAG_VOSRDY)) {}

  /** Initializes the RCC Oscillators according to the specified parameters
  * in the RCC_OscInitTypeDef structure.
  */
  RCC_OscInitStruct.OscillatorType = RCC_OSCILLATORTYPE_HSI48|RCC_OSCILLATORTYPE_HSI;
  RCC_OscInitStruct.HSIState = RCC_HSI_DIV1;
  RCC_OscInitStruct.HSICalibrationValue = RCC_HSICALIBRATION_DEFAULT;
  RCC_OscInitStruct.HSI48State = RCC_HSI48_ON;
  RCC_OscInitStruct.PLL.PLLState = RCC_PLL_ON;
  RCC_OscInitStruct.PLL.PLLSource = RCC_PLLSOURCE_HSI;
  RCC_OscInitStruct.PLL.PLLM = 4;
  RCC_OscInitStruct.PLL.PLLN = 60;
  RCC_OscInitStruct.PLL.PLLP = 2;
  RCC_OscInitStruct.PLL.PLLQ = 5;
  RCC_OscInitStruct.PLL.PLLR = 2;
  RCC_OscInitStruct.PLL.PLLRGE = RCC_PLL1VCIRANGE_3;
  RCC_OscInitStruct.PLL.PLLVCOSEL = RCC_PLL1VCOWIDE;
  RCC_OscInitStruct.PLL.PLLFRACN = 0;
  if (HAL_RCC_OscConfig(&RCC_OscInitStruct) != HAL_OK)
  {
    Error_Handler();
  }

  /** Initializes the CPU, AHB and APB buses clocks
  */
  RCC_ClkInitStruct.ClockType = RCC_CLOCKTYPE_HCLK|RCC_CLOCKTYPE_SYSCLK
                              |RCC_CLOCKTYPE_PCLK1|RCC_CLOCKTYPE_PCLK2
                              |RCC_CLOCKTYPE_D3PCLK1|RCC_CLOCKTYPE_D1PCLK1;
  RCC_ClkInitStruct.SYSCLKSource = RCC_SYSCLKSOURCE_PLLCLK;
  RCC_ClkInitStruct.SYSCLKDivider = RCC_SYSCLK_DIV1;
  RCC_ClkInitStruct.AHBCLKDivider = RCC_HCLK_DIV2;
  RCC_ClkInitStruct.APB3CLKDivider = RCC_APB3_DIV2;
  RCC_ClkInitStruct.APB1CLKDivider = RCC_APB1_DIV2;
  RCC_ClkInitStruct.APB2CLKDivider = RCC_APB2_DIV2;
  RCC_ClkInitStruct.APB4CLKDivider = RCC_APB4_DIV2;

  if (HAL_RCC_ClockConfig(&RCC_ClkInitStruct, FLASH_LATENCY_4) != HAL_OK)
  {
    Error_Handler();
  }
}

void PeriphCommonClock_Config(void)
{
  RCC_PeriphCLKInitTypeDef PeriphClkInitStruct = {0};

  /** Initializes the peripherals clock
  */
  PeriphClkInitStruct.PeriphClockSelection = RCC_PERIPHCLK_ADC|RCC_PERIPHCLK_FDCAN;
  PeriphClkInitStruct.PLL2.PLL2M = 4;
  PeriphClkInitStruct.PLL2.PLL2N = 10;
  PeriphClkInitStruct.PLL2.PLL2P = 2;
  PeriphClkInitStruct.PLL2.PLL2Q = 2;
  PeriphClkInitStruct.PLL2.PLL2R = 2;
  PeriphClkInitStruct.PLL2.PLL2RGE = RCC_PLL2VCIRANGE_3;
  PeriphClkInitStruct.PLL2.PLL2VCOSEL = RCC_PLL2VCOMEDIUM;
  PeriphClkInitStruct.PLL2.PLL2FRACN = 0;
  PeriphClkInitStruct.FdcanClockSelection = RCC_FDCANCLKSOURCE_PLL2;
  PeriphClkInitStruct.AdcClockSelection = RCC_ADCCLKSOURCE_PLL2;
  if (HAL_RCCEx_PeriphCLKConfig(&PeriphClkInitStruct) != HAL_OK)
  {
    Error_Handler();
  }
}

static void MX_ADC1_Init(void)
{

  ADC_MultiModeTypeDef multimode = {0};
  ADC_AnalogWDGConfTypeDef AnalogWDGConfig = {0};
  ADC_InjectionConfTypeDef sConfigInjected = {0};

  /** Common config
  */
  hadc1.Instance = ADC1;
  hadc1.Init.ClockPrescaler = ADC_CLOCK_ASYNC_DIV1;
  hadc1.Init.Resolution = ADC_RESOLUTION_16B;
  hadc1.Init.ScanConvMode = ADC_SCAN_ENABLE;
  hadc1.Init.EOCSelection = ADC_EOC_SEQ_CONV;
  hadc1.Init.LowPowerAutoWait = DISABLE;
  hadc1.Init.ContinuousConvMode = DISABLE;
  hadc1.Init.NbrOfConversion = 1;
  hadc1.Init.DiscontinuousConvMode = DISABLE;
  hadc1.Init.ConversionDataManagement = ADC_CONVERSIONDATA_DR;
  hadc1.Init.Overrun = ADC_OVR_DATA_PRESERVED;
  hadc1.Init.LeftBitShift = ADC_LEFTBITSHIFT_NONE;
  hadc1.Init.OversamplingMode = DISABLE;
  hadc1.Init.Oversampling.Ratio = 1;
  if (HAL_ADC_Init(&hadc1) != HAL_OK)
  {
    Error_Handler();
  }

  /** Configure the ADC multi-mode
  */
  multimode.Mode = ADC_MODE_INDEPENDENT;
  if (HAL_ADCEx_MultiModeConfigChannel(&hadc1, &multimode) != HAL_OK)
  {
    Error_Handler();
  }

  /** Disable Injected Queue
  */
  HAL_ADCEx_DisableInjectedQueue(&hadc1);

  /** Configure Analog WatchDog 1
  */
  AnalogWDGConfig.WatchdogNumber = ADC_ANALOGWATCHDOG_1;
  AnalogWDGConfig.WatchdogMode = ADC_ANALOGWATCHDOG_ALL_INJEC;
  AnalogWDGConfig.ITMode = ENABLE;
  AnalogWDGConfig.HighThreshold = (65535-5000)*8;
  AnalogWDGConfig.LowThreshold = 10000*8;
  if (HAL_ADC_AnalogWDGConfig(&hadc1, &AnalogWDGConfig) != HAL_OK)
  {
    Error_Handler();
  }

  /** Configure Injected Channel
  */
  sConfigInjected.InjectedChannel = ADC_CHANNEL_3;
  sConfigInjected.InjectedRank = ADC_INJECTED_RANK_1;
  sConfigInjected.InjectedSamplingTime = ADC_SAMPLETIME_32CYCLES_5;
  sConfigInjected.InjectedSingleDiff = ADC_SINGLE_ENDED;
  sConfigInjected.InjectedOffsetNumber = ADC_OFFSET_NONE;
  sConfigInjected.InjectedOffset = 0;
  sConfigInjected.InjectedOffsetSignedSaturation = DISABLE;
  sConfigInjected.InjectedNbrOfConversion = 4;
  sConfigInjected.InjectedDiscontinuousConvMode = DISABLE;
  sConfigInjected.AutoInjectedConv = DISABLE;
  sConfigInjected.QueueInjectedContext = DISABLE;
  sConfigInjected.ExternalTrigInjecConv = ADC_EXTERNALTRIGINJEC_T8_TRGO;
  sConfigInjected.ExternalTrigInjecConvEdge = ADC_EXTERNALTRIGINJECCONV_EDGE_RISING;
  sConfigInjected.InjecOversamplingMode = ENABLE;
  sConfigInjected.InjecOversampling.Ratio = 8;
  sConfigInjected.InjecOversampling.RightBitShift = ADC_RIGHTBITSHIFT_3;
  if (HAL_ADCEx_InjectedConfigChannel(&hadc1, &sConfigInjected) != HAL_OK)
  {
    Error_Handler();
  }

  /** Configure Injected Channel
  */
  sConfigInjected.InjectedChannel = ADC_CHANNEL_18;
  sConfigInjected.InjectedRank = ADC_INJECTED_RANK_2;
  if (HAL_ADCEx_InjectedConfigChannel(&hadc1, &sConfigInjected) != HAL_OK)
  {
    Error_Handler();
  }

  /** Configure Injected Channel
  */
  sConfigInjected.InjectedChannel = ADC_CHANNEL_14;
  sConfigInjected.InjectedRank = ADC_INJECTED_RANK_3;
  if (HAL_ADCEx_InjectedConfigChannel(&hadc1, &sConfigInjected) != HAL_OK)
  {
    Error_Handler();
  }

  /** Configure Injected Channel
  */
  sConfigInjected.InjectedChannel = ADC_CHANNEL_4;
  sConfigInjected.InjectedRank = ADC_INJECTED_RANK_4;
  if (HAL_ADCEx_InjectedConfigChannel(&hadc1, &sConfigInjected) != HAL_OK)
  {
    Error_Handler();
  }

}

static void MX_ADC2_Init(void)
{

  ADC_AnalogWDGConfTypeDef AnalogWDGConfig = {0};
  ADC_InjectionConfTypeDef sConfigInjected = {0};

  /** Common config
  */
  hadc2.Instance = ADC2;
  hadc2.Init.ClockPrescaler = ADC_CLOCK_ASYNC_DIV1;
  hadc2.Init.Resolution = ADC_RESOLUTION_16B;
  hadc2.Init.ScanConvMode = ADC_SCAN_ENABLE;
  hadc2.Init.EOCSelection = ADC_EOC_SEQ_CONV;
  hadc2.Init.LowPowerAutoWait = DISABLE;
  hadc2.Init.ContinuousConvMode = DISABLE;
  hadc2.Init.NbrOfConversion = 1;
  hadc2.Init.DiscontinuousConvMode = DISABLE;
  hadc2.Init.ConversionDataManagement = ADC_CONVERSIONDATA_DR;
  hadc2.Init.Overrun = ADC_OVR_DATA_PRESERVED;
  hadc2.Init.LeftBitShift = ADC_LEFTBITSHIFT_NONE;
  hadc2.Init.OversamplingMode = ENABLE;
  hadc2.Init.Oversampling.Ratio = 1;
  if (HAL_ADC_Init(&hadc2) != HAL_OK)
  {
    Error_Handler();
  }

  /** Disable Injected Queue
  */
  HAL_ADCEx_DisableInjectedQueue(&hadc2);

  /** Configure Analog WatchDog 1
  */
  AnalogWDGConfig.WatchdogNumber = ADC_ANALOGWATCHDOG_1;
  AnalogWDGConfig.WatchdogMode = ADC_ANALOGWATCHDOG_ALL_INJEC;
  AnalogWDGConfig.ITMode = ENABLE;
  AnalogWDGConfig.HighThreshold = (65535-5000)*8;
  AnalogWDGConfig.LowThreshold = 10000*8;
  if (HAL_ADC_AnalogWDGConfig(&hadc2, &AnalogWDGConfig) != HAL_OK)
  {
    Error_Handler();
  }

  /** Configure Injected Channel
  */
  sConfigInjected.InjectedChannel = ADC_CHANNEL_7;
  sConfigInjected.InjectedRank = ADC_INJECTED_RANK_1;
  sConfigInjected.InjectedSamplingTime = ADC_SAMPLETIME_32CYCLES_5;
  sConfigInjected.InjectedSingleDiff = ADC_SINGLE_ENDED;
  sConfigInjected.InjectedOffsetNumber = ADC_OFFSET_NONE;
  sConfigInjected.InjectedOffset = 0;
  sConfigInjected.InjectedOffsetSignedSaturation = DISABLE;
  sConfigInjected.InjectedNbrOfConversion = 4;
  sConfigInjected.InjectedDiscontinuousConvMode = DISABLE;
  sConfigInjected.AutoInjectedConv = DISABLE;
  sConfigInjected.QueueInjectedContext = DISABLE;
  sConfigInjected.ExternalTrigInjecConv = ADC_EXTERNALTRIGINJEC_T1_TRGO;
  sConfigInjected.ExternalTrigInjecConvEdge = ADC_EXTERNALTRIGINJECCONV_EDGE_RISING;
  sConfigInjected.InjecOversamplingMode = ENABLE;
  sConfigInjected.InjecOversampling.Ratio = 8;
  sConfigInjected.InjecOversampling.RightBitShift = ADC_RIGHTBITSHIFT_3;
  if (HAL_ADCEx_InjectedConfigChannel(&hadc2, &sConfigInjected) != HAL_OK)
  {
    Error_Handler();
  }

  /** Configure Injected Channel
  */
  sConfigInjected.InjectedChannel = ADC_CHANNEL_8;
  sConfigInjected.InjectedRank = ADC_INJECTED_RANK_2;
  if (HAL_ADCEx_InjectedConfigChannel(&hadc2, &sConfigInjected) != HAL_OK)
  {
    Error_Handler();
  }

  /** Configure Injected Channel
  */
  sConfigInjected.InjectedChannel = ADC_CHANNEL_5;
  sConfigInjected.InjectedRank = ADC_INJECTED_RANK_3;
  if (HAL_ADCEx_InjectedConfigChannel(&hadc2, &sConfigInjected) != HAL_OK)
  {
    Error_Handler();
  }

  /** Configure Injected Channel
  */
  sConfigInjected.InjectedChannel = ADC_CHANNEL_15;
  sConfigInjected.InjectedRank = ADC_INJECTED_RANK_4;
  if (HAL_ADCEx_InjectedConfigChannel(&hadc2, &sConfigInjected) != HAL_OK)
  {
    Error_Handler();
  }

}

static void MX_CRC_Init(void)
{

  hcrc.Instance = CRC;
  hcrc.Init.DefaultPolynomialUse = DEFAULT_POLYNOMIAL_DISABLE;
  hcrc.Init.DefaultInitValueUse = DEFAULT_INIT_VALUE_DISABLE;
  hcrc.Init.GeneratingPolynomial = 7;
  hcrc.Init.CRCLength = CRC_POLYLENGTH_8B;
  hcrc.Init.InitValue = 0;
  hcrc.Init.InputDataInversionMode = CRC_INPUTDATA_INVERSION_NONE;
  hcrc.Init.OutputDataInversionMode = CRC_OUTPUTDATA_INVERSION_DISABLE;
  hcrc.InputDataFormat = CRC_INPUTDATA_FORMAT_BYTES;
  if (HAL_CRC_Init(&hcrc) != HAL_OK)
  {
    Error_Handler();
  }

}

static void MX_FDCAN1_Init(void)
{

  hfdcan1.Instance = FDCAN1;
  hfdcan1.Init.FrameFormat = FDCAN_FRAME_CLASSIC;
  hfdcan1.Init.Mode = FDCAN_MODE_NORMAL;
  hfdcan1.Init.AutoRetransmission = DISABLE;
  hfdcan1.Init.TransmitPause = DISABLE;
  hfdcan1.Init.ProtocolException = DISABLE;
  hfdcan1.Init.NominalPrescaler = 16;
  hfdcan1.Init.NominalSyncJumpWidth = 1;
  hfdcan1.Init.NominalTimeSeg1 = 1;
  hfdcan1.Init.NominalTimeSeg2 = 1;
  hfdcan1.Init.DataPrescaler = 1;
  hfdcan1.Init.DataSyncJumpWidth = 1;
  hfdcan1.Init.DataTimeSeg1 = 1;
  hfdcan1.Init.DataTimeSeg2 = 1;
  hfdcan1.Init.MessageRAMOffset = 0;
  hfdcan1.Init.StdFiltersNbr = 0;
  hfdcan1.Init.ExtFiltersNbr = 0;
  hfdcan1.Init.RxFifo0ElmtsNbr = 0;
  hfdcan1.Init.RxFifo0ElmtSize = FDCAN_DATA_BYTES_8;
  hfdcan1.Init.RxFifo1ElmtsNbr = 0;
  hfdcan1.Init.RxFifo1ElmtSize = FDCAN_DATA_BYTES_8;
  hfdcan1.Init.RxBuffersNbr = 0;
  hfdcan1.Init.RxBufferSize = FDCAN_DATA_BYTES_8;
  hfdcan1.Init.TxEventsNbr = 0;
  hfdcan1.Init.TxBuffersNbr = 0;
  hfdcan1.Init.TxFifoQueueElmtsNbr = 0;
  hfdcan1.Init.TxFifoQueueMode = FDCAN_TX_FIFO_OPERATION;
  hfdcan1.Init.TxElmtSize = FDCAN_DATA_BYTES_8;
  if (HAL_FDCAN_Init(&hfdcan1) != HAL_OK)
  {
    Error_Handler();
  }

}

static void MX_I2C1_Init(void)
{

  hi2c1.Instance = I2C1;
  hi2c1.Init.Timing = 0x307075B1;
  hi2c1.Init.OwnAddress1 = 0;
  hi2c1.Init.AddressingMode = I2C_ADDRESSINGMODE_7BIT;
  hi2c1.Init.DualAddressMode = I2C_DUALADDRESS_DISABLE;
  hi2c1.Init.OwnAddress2 = 0;
  hi2c1.Init.OwnAddress2Masks = I2C_OA2_NOMASK;
  hi2c1.Init.GeneralCallMode = I2C_GENERALCALL_DISABLE;
  hi2c1.Init.NoStretchMode = I2C_NOSTRETCH_DISABLE;
  if (HAL_I2C_Init(&hi2c1) != HAL_OK)
  {
    Error_Handler();
  }

  /** Configure Analogue filter
  */
  if (HAL_I2CEx_ConfigAnalogFilter(&hi2c1, I2C_ANALOGFILTER_ENABLE) != HAL_OK)
  {
    Error_Handler();
  }

  /** Configure Digital filter
  */
  if (HAL_I2CEx_ConfigDigitalFilter(&hi2c1, 0) != HAL_OK)
  {
    Error_Handler();
  }

}

static void MX_I2C2_Init(void)
{

  hi2c2.Instance = I2C2;
  hi2c2.Init.Timing = 0x307075B1;
  hi2c2.Init.OwnAddress1 = 0;
  hi2c2.Init.AddressingMode = I2C_ADDRESSINGMODE_7BIT;
  hi2c2.Init.DualAddressMode = I2C_DUALADDRESS_DISABLE;
  hi2c2.Init.OwnAddress2 = 0;
  hi2c2.Init.OwnAddress2Masks = I2C_OA2_NOMASK;
  hi2c2.Init.GeneralCallMode = I2C_GENERALCALL_DISABLE;
  hi2c2.Init.NoStretchMode = I2C_NOSTRETCH_DISABLE;
  if (HAL_I2C_Init(&hi2c2) != HAL_OK)
  {
    Error_Handler();
  }

  /** Configure Analogue filter
  */
  if (HAL_I2CEx_ConfigAnalogFilter(&hi2c2, I2C_ANALOGFILTER_ENABLE) != HAL_OK)
  {
    Error_Handler();
  }

  /** Configure Digital filter
  */
  if (HAL_I2CEx_ConfigDigitalFilter(&hi2c2, 0) != HAL_OK)
  {
    Error_Handler();
  }

}

static void MX_QUADSPI_Init(void)
{

  /* QUADSPI parameter configuration*/
  hqspi.Instance = QUADSPI;
  hqspi.Init.ClockPrescaler = 255;
  hqspi.Init.FifoThreshold = 1;
  hqspi.Init.SampleShifting = QSPI_SAMPLE_SHIFTING_NONE;
  hqspi.Init.FlashSize = 1;
  hqspi.Init.ChipSelectHighTime = QSPI_CS_HIGH_TIME_1_CYCLE;
  hqspi.Init.ClockMode = QSPI_CLOCK_MODE_0;
  hqspi.Init.FlashID = QSPI_FLASH_ID_1;
  hqspi.Init.DualFlash = QSPI_DUALFLASH_DISABLE;
  if (HAL_QSPI_Init(&hqspi) != HAL_OK)
  {
    Error_Handler();
  }

}

static void MX_SPI2_Init(void)
{

  /* SPI2 parameter configuration*/
  hspi2.Instance = SPI2;
  hspi2.Init.Mode = SPI_MODE_MASTER;
  hspi2.Init.Direction = SPI_DIRECTION_2LINES;
  hspi2.Init.DataSize = SPI_DATASIZE_8BIT;
  hspi2.Init.CLKPolarity = SPI_POLARITY_LOW;
  hspi2.Init.CLKPhase = SPI_PHASE_2EDGE;
  hspi2.Init.NSS = SPI_NSS_SOFT;
  hspi2.Init.BaudRatePrescaler = SPI_BAUDRATEPRESCALER_128;
  hspi2.Init.FirstBit = SPI_FIRSTBIT_MSB;
  hspi2.Init.TIMode = SPI_TIMODE_DISABLE;
  hspi2.Init.CRCCalculation = SPI_CRCCALCULATION_DISABLE;
  hspi2.Init.CRCPolynomial = 0x0;
  hspi2.Init.NSSPMode = SPI_NSS_PULSE_ENABLE;
  hspi2.Init.NSSPolarity = SPI_NSS_POLARITY_LOW;
  hspi2.Init.FifoThreshold = SPI_FIFO_THRESHOLD_01DATA;
  hspi2.Init.TxCRCInitializationPattern = SPI_CRC_INITIALIZATION_ALL_ZERO_PATTERN;
  hspi2.Init.RxCRCInitializationPattern = SPI_CRC_INITIALIZATION_ALL_ZERO_PATTERN;
  hspi2.Init.MasterSSIdleness = SPI_MASTER_SS_IDLENESS_00CYCLE;
  hspi2.Init.MasterInterDataIdleness = SPI_MASTER_INTERDATA_IDLENESS_00CYCLE;
  hspi2.Init.MasterReceiverAutoSusp = SPI_MASTER_RX_AUTOSUSP_DISABLE;
  hspi2.Init.MasterKeepIOState = SPI_MASTER_KEEP_IO_STATE_DISABLE;
  hspi2.Init.IOSwap = SPI_IO_SWAP_DISABLE;
  if (HAL_SPI_Init(&hspi2) != HAL_OK)
  {
    Error_Handler();
  }

}

static void MX_SPI3_Init(void)
{

  /* SPI3 parameter configuration*/
  hspi3.Instance = SPI3;
  hspi3.Init.Mode = SPI_MODE_MASTER;
  hspi3.Init.Direction = SPI_DIRECTION_2LINES;
  hspi3.Init.DataSize = SPI_DATASIZE_8BIT;
  hspi3.Init.CLKPolarity = SPI_POLARITY_HIGH;
  hspi3.Init.CLKPhase = SPI_PHASE_2EDGE;
  hspi3.Init.NSS = SPI_NSS_SOFT;
  hspi3.Init.BaudRatePrescaler = SPI_BAUDRATEPRESCALER_16;
  hspi3.Init.FirstBit = SPI_FIRSTBIT_MSB;
  hspi3.Init.TIMode = SPI_TIMODE_DISABLE;
  hspi3.Init.CRCCalculation = SPI_CRCCALCULATION_DISABLE;
  hspi3.Init.CRCPolynomial = 0x0;
  hspi3.Init.NSSPMode = SPI_NSS_PULSE_ENABLE;
  hspi3.Init.NSSPolarity = SPI_NSS_POLARITY_LOW;
  hspi3.Init.FifoThreshold = SPI_FIFO_THRESHOLD_01DATA;
  hspi3.Init.TxCRCInitializationPattern = SPI_CRC_INITIALIZATION_ALL_ZERO_PATTERN;
  hspi3.Init.RxCRCInitializationPattern = SPI_CRC_INITIALIZATION_ALL_ZERO_PATTERN;
  hspi3.Init.MasterSSIdleness = SPI_MASTER_SS_IDLENESS_02CYCLE;
  hspi3.Init.MasterInterDataIdleness = SPI_MASTER_INTERDATA_IDLENESS_00CYCLE;
  hspi3.Init.MasterReceiverAutoSusp = SPI_MASTER_RX_AUTOSUSP_DISABLE;
  hspi3.Init.MasterKeepIOState = SPI_MASTER_KEEP_IO_STATE_DISABLE;
  hspi3.Init.IOSwap = SPI_IO_SWAP_DISABLE;
  if (HAL_SPI_Init(&hspi3) != HAL_OK)
  {
    Error_Handler();
  }

}

static void MX_TIM1_Init(void)
{

  TIM_ClockConfigTypeDef sClockSourceConfig = {0};
  TIM_MasterConfigTypeDef sMasterConfig = {0};
  TIM_OC_InitTypeDef sConfigOC = {0};
  TIM_BreakDeadTimeConfigTypeDef sBreakDeadTimeConfig = {0};

  htim1.Instance = TIM1;
  htim1.Init.Prescaler = 0;
  htim1.Init.CounterMode = TIM_COUNTERMODE_CENTERALIGNED1;
  htim1.Init.Period = 6000-1;
  htim1.Init.ClockDivision = TIM_CLOCKDIVISION_DIV1;
  htim1.Init.RepetitionCounter = 0;
  htim1.Init.AutoReloadPreload = TIM_AUTORELOAD_PRELOAD_ENABLE;
  if (HAL_TIM_Base_Init(&htim1) != HAL_OK)
  {
    Error_Handler();
  }
  sClockSourceConfig.ClockSource = TIM_CLOCKSOURCE_INTERNAL;
  if (HAL_TIM_ConfigClockSource(&htim1, &sClockSourceConfig) != HAL_OK)
  {
    Error_Handler();
  }
  if (HAL_TIM_PWM_Init(&htim1) != HAL_OK)
  {
    Error_Handler();
  }
  if (HAL_TIM_OC_Init(&htim1) != HAL_OK)
  {
    Error_Handler();
  }
  sMasterConfig.MasterOutputTrigger = TIM_TRGO_OC4REF;
  sMasterConfig.MasterOutputTrigger2 = TIM_TRGO2_RESET;
  sMasterConfig.MasterSlaveMode = TIM_MASTERSLAVEMODE_DISABLE;
  if (HAL_TIMEx_MasterConfigSynchronization(&htim1, &sMasterConfig) != HAL_OK)
  {
    Error_Handler();
  }
  sConfigOC.OCMode = TIM_OCMODE_PWM1;
  sConfigOC.Pulse = 3000-1;
  sConfigOC.OCPolarity = TIM_OCPOLARITY_HIGH;
  sConfigOC.OCNPolarity = TIM_OCNPOLARITY_HIGH;
  sConfigOC.OCFastMode = TIM_OCFAST_DISABLE;
  sConfigOC.OCIdleState = TIM_OCIDLESTATE_RESET;
  sConfigOC.OCNIdleState = TIM_OCNIDLESTATE_RESET;
  if (HAL_TIM_PWM_ConfigChannel(&htim1, &sConfigOC, TIM_CHANNEL_1) != HAL_OK)
  {
    Error_Handler();
  }
  if (HAL_TIM_PWM_ConfigChannel(&htim1, &sConfigOC, TIM_CHANNEL_2) != HAL_OK)
  {
    Error_Handler();
  }
  if (HAL_TIM_PWM_ConfigChannel(&htim1, &sConfigOC, TIM_CHANNEL_3) != HAL_OK)
  {
    Error_Handler();
  }
  sConfigOC.OCMode = TIM_OCMODE_TOGGLE;
  sConfigOC.Pulse = 1;
  if (HAL_TIM_OC_ConfigChannel(&htim1, &sConfigOC, TIM_CHANNEL_4) != HAL_OK)
  {
    Error_Handler();
  }
  sBreakDeadTimeConfig.OffStateRunMode = TIM_OSSR_ENABLE;
  sBreakDeadTimeConfig.OffStateIDLEMode = TIM_OSSI_ENABLE;
  sBreakDeadTimeConfig.LockLevel = TIM_LOCKLEVEL_OFF;
  sBreakDeadTimeConfig.DeadTime = 40;
  sBreakDeadTimeConfig.BreakState = TIM_BREAK_DISABLE;
  sBreakDeadTimeConfig.BreakPolarity = TIM_BREAKPOLARITY_HIGH;
  sBreakDeadTimeConfig.BreakFilter = 0;
  sBreakDeadTimeConfig.Break2State = TIM_BREAK2_DISABLE;
  sBreakDeadTimeConfig.Break2Polarity = TIM_BREAK2POLARITY_HIGH;
  sBreakDeadTimeConfig.Break2Filter = 0;
  sBreakDeadTimeConfig.AutomaticOutput = TIM_AUTOMATICOUTPUT_DISABLE;
  if (HAL_TIMEx_ConfigBreakDeadTime(&htim1, &sBreakDeadTimeConfig) != HAL_OK)
  {
    Error_Handler();
  }
  HAL_TIM_MspPostInit(&htim1);

}

static void MX_TIM2_Init(void)
{

  TIM_ClockConfigTypeDef sClockSourceConfig = {0};
  TIM_MasterConfigTypeDef sMasterConfig = {0};
  TIM_IC_InitTypeDef sConfigIC = {0};

  htim2.Instance = TIM2;
  htim2.Init.Prescaler = 0;
  htim2.Init.CounterMode = TIM_COUNTERMODE_UP;
  htim2.Init.Period = 4294967295;
  htim2.Init.ClockDivision = TIM_CLOCKDIVISION_DIV1;
  htim2.Init.AutoReloadPreload = TIM_AUTORELOAD_PRELOAD_DISABLE;
  if (HAL_TIM_Base_Init(&htim2) != HAL_OK)
  {
    Error_Handler();
  }
  sClockSourceConfig.ClockSource = TIM_CLOCKSOURCE_INTERNAL;
  if (HAL_TIM_ConfigClockSource(&htim2, &sClockSourceConfig) != HAL_OK)
  {
    Error_Handler();
  }
  if (HAL_TIM_IC_Init(&htim2) != HAL_OK)
  {
    Error_Handler();
  }
  sMasterConfig.MasterOutputTrigger = TIM_TRGO_RESET;
  sMasterConfig.MasterSlaveMode = TIM_MASTERSLAVEMODE_DISABLE;
  if (HAL_TIMEx_MasterConfigSynchronization(&htim2, &sMasterConfig) != HAL_OK)
  {
    Error_Handler();
  }
  sConfigIC.ICPolarity = TIM_INPUTCHANNELPOLARITY_BOTHEDGE;
  sConfigIC.ICSelection = TIM_ICSELECTION_DIRECTTI;
  sConfigIC.ICPrescaler = TIM_ICPSC_DIV1;
  sConfigIC.ICFilter = 0;
  if (HAL_TIM_IC_ConfigChannel(&htim2, &sConfigIC, TIM_CHANNEL_1) != HAL_OK)
  {
    Error_Handler();
  }
  if (HAL_TIM_IC_ConfigChannel(&htim2, &sConfigIC, TIM_CHANNEL_2) != HAL_OK)
  {
    Error_Handler();
  }

}

static void MX_TIM3_Init(void)
{

  TIM_ClockConfigTypeDef sClockSourceConfig = {0};
  TIM_SlaveConfigTypeDef sSlaveConfig = {0};
  TIM_MasterConfigTypeDef sMasterConfig = {0};
  TIM_IC_InitTypeDef sConfigIC = {0};

  htim3.Instance = TIM3;
  htim3.Init.Prescaler = 240-1;
  htim3.Init.CounterMode = TIM_COUNTERMODE_UP;
  htim3.Init.Period = 65535;
  htim3.Init.ClockDivision = TIM_CLOCKDIVISION_DIV1;
  htim3.Init.AutoReloadPreload = TIM_AUTORELOAD_PRELOAD_DISABLE;
  if (HAL_TIM_Base_Init(&htim3) != HAL_OK)
  {
    Error_Handler();
  }
  sClockSourceConfig.ClockSource = TIM_CLOCKSOURCE_INTERNAL;
  if (HAL_TIM_ConfigClockSource(&htim3, &sClockSourceConfig) != HAL_OK)
  {
    Error_Handler();
  }
  if (HAL_TIM_IC_Init(&htim3) != HAL_OK)
  {
    Error_Handler();
  }
  sSlaveConfig.SlaveMode = TIM_SLAVEMODE_TRIGGER;
  sSlaveConfig.InputTrigger = TIM_TS_ITR3;
  if (HAL_TIM_SlaveConfigSynchro(&htim3, &sSlaveConfig) != HAL_OK)
  {
    Error_Handler();
  }
  sMasterConfig.MasterOutputTrigger = TIM_TRGO_UPDATE;
  sMasterConfig.MasterSlaveMode = TIM_MASTERSLAVEMODE_DISABLE;
  if (HAL_TIMEx_MasterConfigSynchronization(&htim3, &sMasterConfig) != HAL_OK)
  {
    Error_Handler();
  }
  sConfigIC.ICPolarity = TIM_INPUTCHANNELPOLARITY_RISING;
  sConfigIC.ICSelection = TIM_ICSELECTION_DIRECTTI;
  sConfigIC.ICPrescaler = TIM_ICPSC_DIV1;
  sConfigIC.ICFilter = 0;
  if (HAL_TIM_IC_ConfigChannel(&htim3, &sConfigIC, TIM_CHANNEL_1) != HAL_OK)
  {
    Error_Handler();
  }

}

static void MX_TIM4_Init(void)
{

  TIM_ClockConfigTypeDef sClockSourceConfig = {0};
  TIM_MasterConfigTypeDef sMasterConfig = {0};
  TIM_OC_InitTypeDef sConfigOC = {0};

  htim4.Instance = TIM4;
  htim4.Init.Prescaler = 65535;
  htim4.Init.CounterMode = TIM_COUNTERMODE_UP;
  htim4.Init.Period = 65535;
  htim4.Init.ClockDivision = TIM_CLOCKDIVISION_DIV4;
  htim4.Init.AutoReloadPreload = TIM_AUTORELOAD_PRELOAD_DISABLE;
  if (HAL_TIM_Base_Init(&htim4) != HAL_OK)
  {
    Error_Handler();
  }
  sClockSourceConfig.ClockSource = TIM_CLOCKSOURCE_INTERNAL;
  if (HAL_TIM_ConfigClockSource(&htim4, &sClockSourceConfig) != HAL_OK)
  {
    Error_Handler();
  }
  if (HAL_TIM_OC_Init(&htim4) != HAL_OK)
  {
    Error_Handler();
  }
  if (HAL_TIM_OnePulse_Init(&htim4, TIM_OPMODE_SINGLE) != HAL_OK)
  {
    Error_Handler();
  }
  sMasterConfig.MasterOutputTrigger = TIM_TRGO_OC1REF;
  sMasterConfig.MasterSlaveMode = TIM_MASTERSLAVEMODE_DISABLE;
  if (HAL_TIMEx_MasterConfigSynchronization(&htim4, &sMasterConfig) != HAL_OK)
  {
    Error_Handler();
  }
  sConfigOC.OCMode = TIM_OCMODE_ACTIVE;
  sConfigOC.Pulse = 2;
  sConfigOC.OCPolarity = TIM_OCPOLARITY_HIGH;
  sConfigOC.OCFastMode = TIM_OCFAST_DISABLE;
  if (HAL_TIM_OC_ConfigChannel(&htim4, &sConfigOC, TIM_CHANNEL_1) != HAL_OK)
  {
    Error_Handler();
  }

}

static void MX_TIM5_Init(void)
{

  TIM_ClockConfigTypeDef sClockSourceConfig = {0};
  TIM_MasterConfigTypeDef sMasterConfig = {0};
  TIM_IC_InitTypeDef sConfigIC = {0};

  htim5.Instance = TIM5;
  htim5.Init.Prescaler = 0;
  htim5.Init.CounterMode = TIM_COUNTERMODE_UP;
  htim5.Init.Period = 4294967295;
  htim5.Init.ClockDivision = TIM_CLOCKDIVISION_DIV1;
  htim5.Init.AutoReloadPreload = TIM_AUTORELOAD_PRELOAD_DISABLE;
  if (HAL_TIM_Base_Init(&htim5) != HAL_OK)
  {
    Error_Handler();
  }
  sClockSourceConfig.ClockSource = TIM_CLOCKSOURCE_INTERNAL;
  if (HAL_TIM_ConfigClockSource(&htim5, &sClockSourceConfig) != HAL_OK)
  {
    Error_Handler();
  }
  if (HAL_TIM_IC_Init(&htim5) != HAL_OK)
  {
    Error_Handler();
  }
  sMasterConfig.MasterOutputTrigger = TIM_TRGO_RESET;
  sMasterConfig.MasterSlaveMode = TIM_MASTERSLAVEMODE_DISABLE;
  if (HAL_TIMEx_MasterConfigSynchronization(&htim5, &sMasterConfig) != HAL_OK)
  {
    Error_Handler();
  }
  sConfigIC.ICPolarity = TIM_INPUTCHANNELPOLARITY_BOTHEDGE;
  sConfigIC.ICSelection = TIM_ICSELECTION_DIRECTTI;
  sConfigIC.ICPrescaler = TIM_ICPSC_DIV1;
  sConfigIC.ICFilter = 5;
  if (HAL_TIM_IC_ConfigChannel(&htim5, &sConfigIC, TIM_CHANNEL_1) != HAL_OK)
  {
    Error_Handler();
  }
  if (HAL_TIM_IC_ConfigChannel(&htim5, &sConfigIC, TIM_CHANNEL_2) != HAL_OK)
  {
    Error_Handler();
  }

}

static void MX_TIM6_Init(void)
{

  TIM_MasterConfigTypeDef sMasterConfig = {0};

  htim6.Instance = TIM6;
  htim6.Init.Prescaler = 240-1;
  htim6.Init.CounterMode = TIM_COUNTERMODE_UP;
  htim6.Init.Period = 65535;
  htim6.Init.AutoReloadPreload = TIM_AUTORELOAD_PRELOAD_ENABLE;
  if (HAL_TIM_Base_Init(&htim6) != HAL_OK)
  {
    Error_Handler();
  }
  sMasterConfig.MasterOutputTrigger = TIM_TRGO_RESET;
  sMasterConfig.MasterSlaveMode = TIM_MASTERSLAVEMODE_DISABLE;
  if (HAL_TIMEx_MasterConfigSynchronization(&htim6, &sMasterConfig) != HAL_OK)
  {
    Error_Handler();
  }

}

static void MX_TIM7_Init(void)
{

  TIM_MasterConfigTypeDef sMasterConfig = {0};

  htim7.Instance = TIM7;
  htim7.Init.Prescaler = 240-1;
  htim7.Init.CounterMode = TIM_COUNTERMODE_UP;
  htim7.Init.Period = 1000-1;
  htim7.Init.AutoReloadPreload = TIM_AUTORELOAD_PRELOAD_ENABLE;
  if (HAL_TIM_Base_Init(&htim7) != HAL_OK)
  {
    Error_Handler();
  }
  sMasterConfig.MasterOutputTrigger = TIM_TRGO_RESET;
  sMasterConfig.MasterSlaveMode = TIM_MASTERSLAVEMODE_DISABLE;
  if (HAL_TIMEx_MasterConfigSynchronization(&htim7, &sMasterConfig) != HAL_OK)
  {
    Error_Handler();
  }

}

static void MX_TIM8_Init(void)
{

  TIM_ClockConfigTypeDef sClockSourceConfig = {0};
  TIM_MasterConfigTypeDef sMasterConfig = {0};
  TIM_OC_InitTypeDef sConfigOC = {0};
  TIM_BreakDeadTimeConfigTypeDef sBreakDeadTimeConfig = {0};

  htim8.Instance = TIM8;
  htim8.Init.Prescaler = 0;
  htim8.Init.CounterMode = TIM_COUNTERMODE_CENTERALIGNED1;
  htim8.Init.Period = 6000-1;
  htim8.Init.ClockDivision = TIM_CLOCKDIVISION_DIV1;
  htim8.Init.RepetitionCounter = 0;
  htim8.Init.AutoReloadPreload = TIM_AUTORELOAD_PRELOAD_ENABLE;
  if (HAL_TIM_Base_Init(&htim8) != HAL_OK)
  {
    Error_Handler();
  }
  sClockSourceConfig.ClockSource = TIM_CLOCKSOURCE_INTERNAL;
  if (HAL_TIM_ConfigClockSource(&htim8, &sClockSourceConfig) != HAL_OK)
  {
    Error_Handler();
  }
  if (HAL_TIM_PWM_Init(&htim8) != HAL_OK)
  {
    Error_Handler();
  }
  if (HAL_TIM_OC_Init(&htim8) != HAL_OK)
  {
    Error_Handler();
  }
  sMasterConfig.MasterOutputTrigger = TIM_TRGO_OC4REF;
  sMasterConfig.MasterOutputTrigger2 = TIM_TRGO2_RESET;
  sMasterConfig.MasterSlaveMode = TIM_MASTERSLAVEMODE_DISABLE;
  if (HAL_TIMEx_MasterConfigSynchronization(&htim8, &sMasterConfig) != HAL_OK)
  {
    Error_Handler();
  }
  sConfigOC.OCMode = TIM_OCMODE_PWM1;
  sConfigOC.Pulse = 3000-1;
  sConfigOC.OCPolarity = TIM_OCPOLARITY_HIGH;
  sConfigOC.OCNPolarity = TIM_OCNPOLARITY_HIGH;
  sConfigOC.OCFastMode = TIM_OCFAST_DISABLE;
  sConfigOC.OCIdleState = TIM_OCIDLESTATE_RESET;
  sConfigOC.OCNIdleState = TIM_OCNIDLESTATE_RESET;
  if (HAL_TIM_PWM_ConfigChannel(&htim8, &sConfigOC, TIM_CHANNEL_1) != HAL_OK)
  {
    Error_Handler();
  }
  if (HAL_TIM_PWM_ConfigChannel(&htim8, &sConfigOC, TIM_CHANNEL_2) != HAL_OK)
  {
    Error_Handler();
  }
  if (HAL_TIM_PWM_ConfigChannel(&htim8, &sConfigOC, TIM_CHANNEL_3) != HAL_OK)
  {
    Error_Handler();
  }
  sConfigOC.OCMode = TIM_OCMODE_TOGGLE;
  sConfigOC.Pulse = 1;
  if (HAL_TIM_OC_ConfigChannel(&htim8, &sConfigOC, TIM_CHANNEL_4) != HAL_OK)
  {
    Error_Handler();
  }
  sBreakDeadTimeConfig.OffStateRunMode = TIM_OSSR_ENABLE;
  sBreakDeadTimeConfig.OffStateIDLEMode = TIM_OSSI_ENABLE;
  sBreakDeadTimeConfig.LockLevel = TIM_LOCKLEVEL_OFF;
  sBreakDeadTimeConfig.DeadTime = 40;
  sBreakDeadTimeConfig.BreakState = TIM_BREAK_DISABLE;
  sBreakDeadTimeConfig.BreakPolarity = TIM_BREAKPOLARITY_HIGH;
  sBreakDeadTimeConfig.BreakFilter = 0;
  sBreakDeadTimeConfig.Break2State = TIM_BREAK2_DISABLE;
  sBreakDeadTimeConfig.Break2Polarity = TIM_BREAK2POLARITY_HIGH;
  sBreakDeadTimeConfig.Break2Filter = 0;
  sBreakDeadTimeConfig.AutomaticOutput = TIM_AUTOMATICOUTPUT_DISABLE;
  if (HAL_TIMEx_ConfigBreakDeadTime(&htim8, &sBreakDeadTimeConfig) != HAL_OK)
  {
    Error_Handler();
  }
  HAL_TIM_MspPostInit(&htim8);

}

static void MX_TIM12_Init(void)
{

  TIM_ClockConfigTypeDef sClockSourceConfig = {0};
  TIM_SlaveConfigTypeDef sSlaveConfig = {0};
  TIM_MasterConfigTypeDef sMasterConfig = {0};
  TIM_IC_InitTypeDef sConfigIC = {0};

  htim12.Instance = TIM12;
  htim12.Init.Prescaler = 240-1;
  htim12.Init.CounterMode = TIM_COUNTERMODE_UP;
  htim12.Init.Period = 65535;
  htim12.Init.ClockDivision = TIM_CLOCKDIVISION_DIV1;
  htim12.Init.AutoReloadPreload = TIM_AUTORELOAD_PRELOAD_DISABLE;
  if (HAL_TIM_Base_Init(&htim12) != HAL_OK)
  {
    Error_Handler();
  }
  sClockSourceConfig.ClockSource = TIM_CLOCKSOURCE_INTERNAL;
  if (HAL_TIM_ConfigClockSource(&htim12, &sClockSourceConfig) != HAL_OK)
  {
    Error_Handler();
  }
  if (HAL_TIM_IC_Init(&htim12) != HAL_OK)
  {
    Error_Handler();
  }
  sSlaveConfig.SlaveMode = TIM_SLAVEMODE_TRIGGER;
  sSlaveConfig.InputTrigger = TIM_TS_ITR0;
  if (HAL_TIM_SlaveConfigSynchro(&htim12, &sSlaveConfig) != HAL_OK)
  {
    Error_Handler();
  }
  sMasterConfig.MasterOutputTrigger = TIM_TRGO_RESET;
  sMasterConfig.MasterSlaveMode = TIM_MASTERSLAVEMODE_DISABLE;
  if (HAL_TIMEx_MasterConfigSynchronization(&htim12, &sMasterConfig) != HAL_OK)
  {
    Error_Handler();
  }
  sConfigIC.ICPolarity = TIM_INPUTCHANNELPOLARITY_RISING;
  sConfigIC.ICSelection = TIM_ICSELECTION_DIRECTTI;
  sConfigIC.ICPrescaler = TIM_ICPSC_DIV1;
  sConfigIC.ICFilter = 0;
  if (HAL_TIM_IC_ConfigChannel(&htim12, &sConfigIC, TIM_CHANNEL_1) != HAL_OK)
  {
    Error_Handler();
  }

}

static void MX_USART1_UART_Init(void)
{

  huart1.Instance = USART1;
  huart1.Init.BaudRate = 115200;
  huart1.Init.WordLength = UART_WORDLENGTH_8B;
  huart1.Init.StopBits = UART_STOPBITS_1;
  huart1.Init.Parity = UART_PARITY_NONE;
  huart1.Init.Mode = UART_MODE_TX_RX;
  huart1.Init.HwFlowCtl = UART_HWCONTROL_NONE;
  huart1.Init.OverSampling = UART_OVERSAMPLING_16;
  huart1.Init.OneBitSampling = UART_ONE_BIT_SAMPLE_DISABLE;
  huart1.Init.ClockPrescaler = UART_PRESCALER_DIV1;
  huart1.AdvancedInit.AdvFeatureInit = UART_ADVFEATURE_NO_INIT;
  if (HAL_UART_Init(&huart1) != HAL_OK)
  {
    Error_Handler();
  }
  if (HAL_UARTEx_SetTxFifoThreshold(&huart1, UART_TXFIFO_THRESHOLD_1_8) != HAL_OK)
  {
    Error_Handler();
  }
  if (HAL_UARTEx_SetRxFifoThreshold(&huart1, UART_RXFIFO_THRESHOLD_1_8) != HAL_OK)
  {
    Error_Handler();
  }
  if (HAL_UARTEx_DisableFifoMode(&huart1) != HAL_OK)
  {
    Error_Handler();
  }

}

static void MX_USART2_UART_Init(void)
{

  huart2.Instance = USART2;
  huart2.Init.BaudRate = 115200;
  huart2.Init.WordLength = UART_WORDLENGTH_8B;
  huart2.Init.StopBits = UART_STOPBITS_1;
  huart2.Init.Parity = UART_PARITY_NONE;
  huart2.Init.Mode = UART_MODE_TX_RX;
  huart2.Init.HwFlowCtl = UART_HWCONTROL_NONE;
  huart2.Init.OverSampling = UART_OVERSAMPLING_16;
  huart2.Init.OneBitSampling = UART_ONE_BIT_SAMPLE_DISABLE;
  huart2.Init.ClockPrescaler = UART_PRESCALER_DIV1;
  huart2.AdvancedInit.AdvFeatureInit = UART_ADVFEATURE_NO_INIT;
  if (HAL_UART_Init(&huart2) != HAL_OK)
  {
    Error_Handler();
  }
  if (HAL_UARTEx_SetTxFifoThreshold(&huart2, UART_TXFIFO_THRESHOLD_1_8) != HAL_OK)
  {
    Error_Handler();
  }
  if (HAL_UARTEx_SetRxFifoThreshold(&huart2, UART_RXFIFO_THRESHOLD_1_8) != HAL_OK)
  {
    Error_Handler();
  }
  if (HAL_UARTEx_DisableFifoMode(&huart2) != HAL_OK)
  {
    Error_Handler();
  }

}

static void MX_DMA_Init(void)
{

  /* DMA controller clock enable */
  __HAL_RCC_DMA1_CLK_ENABLE();
  __HAL_RCC_DMA2_CLK_ENABLE();

  /* DMA interrupt init */
  /* DMA1_Stream0_IRQn interrupt configuration */
  HAL_NVIC_SetPriority(DMA1_Stream0_IRQn, 1, 0);
  HAL_NVIC_EnableIRQ(DMA1_Stream0_IRQn);
  /* DMA1_Stream1_IRQn interrupt configuration */
  HAL_NVIC_SetPriority(DMA1_Stream1_IRQn, 1, 0);
  HAL_NVIC_EnableIRQ(DMA1_Stream1_IRQn);
  /* DMA1_Stream2_IRQn interrupt configuration */
  HAL_NVIC_SetPriority(DMA1_Stream2_IRQn, 3, 0);
  HAL_NVIC_EnableIRQ(DMA1_Stream2_IRQn);
  /* DMA1_Stream3_IRQn interrupt configuration */
  HAL_NVIC_SetPriority(DMA1_Stream3_IRQn, 3, 0);
  HAL_NVIC_EnableIRQ(DMA1_Stream3_IRQn);
  /* DMA1_Stream4_IRQn interrupt configuration */
  HAL_NVIC_SetPriority(DMA1_Stream4_IRQn, 3, 0);
  HAL_NVIC_EnableIRQ(DMA1_Stream4_IRQn);
  /* DMA1_Stream5_IRQn interrupt configuration */
  HAL_NVIC_SetPriority(DMA1_Stream5_IRQn, 3, 0);
  HAL_NVIC_EnableIRQ(DMA1_Stream5_IRQn);
  /* DMA1_Stream6_IRQn interrupt configuration */
  HAL_NVIC_SetPriority(DMA1_Stream6_IRQn, 0, 0);
  HAL_NVIC_EnableIRQ(DMA1_Stream6_IRQn);
  /* DMA1_Stream7_IRQn interrupt configuration */
  HAL_NVIC_SetPriority(DMA1_Stream7_IRQn, 0, 0);
  HAL_NVIC_EnableIRQ(DMA1_Stream7_IRQn);
  /* DMA2_Stream0_IRQn interrupt configuration */
  HAL_NVIC_SetPriority(DMA2_Stream0_IRQn, 0, 0);
  HAL_NVIC_EnableIRQ(DMA2_Stream0_IRQn);
  /* DMA2_Stream1_IRQn interrupt configuration */
  HAL_NVIC_SetPriority(DMA2_Stream1_IRQn, 0, 0);
  HAL_NVIC_EnableIRQ(DMA2_Stream1_IRQn);
  /* DMA2_Stream2_IRQn interrupt configuration */
  HAL_NVIC_SetPriority(DMA2_Stream2_IRQn, 0, 0);
  HAL_NVIC_EnableIRQ(DMA2_Stream2_IRQn);
  /* DMA2_Stream3_IRQn interrupt configuration */
  HAL_NVIC_SetPriority(DMA2_Stream3_IRQn, 0, 0);
  HAL_NVIC_EnableIRQ(DMA2_Stream3_IRQn);

}

static void MX_GPIO_Init(void)
{
  GPIO_InitTypeDef GPIO_InitStruct = {0};

  /* GPIO Ports Clock Enable */
  __HAL_RCC_GPIOE_CLK_ENABLE();
  __HAL_RCC_GPIOC_CLK_ENABLE();
  __HAL_RCC_GPIOH_CLK_ENABLE();
  __HAL_RCC_GPIOA_CLK_ENABLE();
  __HAL_RCC_GPIOB_CLK_ENABLE();
  __HAL_RCC_GPIOD_CLK_ENABLE();

  /*Configure GPIO pin Output Level */
  HAL_GPIO_WritePin(GPIOE, M2_DRIVER_NCS_Pin|E2_NCS_Pin|M1_DRIVER_NCS_Pin|ADC2_NCS_Pin
                          |AUX_NCS_Pin, GPIO_PIN_SET);

  /*Configure GPIO pin Output Level */
  HAL_GPIO_WritePin(GPIOE, M2_DRIVER_EN_Pin|M1_DRIVER_EN_Pin, GPIO_PIN_RESET);

  /*Configure GPIO pin Output Level */
  HAL_GPIO_WritePin(STATUS_LED_GPIO_Port, STATUS_LED_Pin, GPIO_PIN_RESET);

  /*Configure GPIO pin Output Level */
  HAL_GPIO_WritePin(GPIOC, ADC1_NCS_Pin|E1_NCS_Pin, GPIO_PIN_SET);

  /*Configure GPIO pin Output Level */
  HAL_GPIO_WritePin(PROBE_OUT_GPIO_Port, PROBE_OUT_Pin, GPIO_PIN_RESET);

  /*Configure GPIO pins : M2_DRIVER_NCS_Pin M2_DRIVER_EN_Pin E2_NCS_Pin M1_DRIVER_NCS_Pin
                           M1_DRIVER_EN_Pin ADC2_NCS_Pin AUX_NCS_Pin */
  GPIO_InitStruct.Pin = M2_DRIVER_NCS_Pin|M2_DRIVER_EN_Pin|E2_NCS_Pin|M1_DRIVER_NCS_Pin
                          |M1_DRIVER_EN_Pin|ADC2_NCS_Pin|AUX_NCS_Pin;
  GPIO_InitStruct.Mode = GPIO_MODE_OUTPUT_PP;
  GPIO_InitStruct.Pull = GPIO_NOPULL;
  GPIO_InitStruct.Speed = GPIO_SPEED_FREQ_LOW;
  HAL_GPIO_Init(GPIOE, &GPIO_InitStruct);

  /*Configure GPIO pins : STATUS_LED_Pin ADC1_NCS_Pin E1_NCS_Pin */
  GPIO_InitStruct.Pin = STATUS_LED_Pin|ADC1_NCS_Pin|E1_NCS_Pin;
  GPIO_InitStruct.Mode = GPIO_MODE_OUTPUT_PP;
  GPIO_InitStruct.Pull = GPIO_NOPULL;
  GPIO_InitStruct.Speed = GPIO_SPEED_FREQ_LOW;
  HAL_GPIO_Init(GPIOC, &GPIO_InitStruct);

  /*Configure GPIO pin : E_STOP_Pin */
  GPIO_InitStruct.Pin = E_STOP_Pin;
  GPIO_InitStruct.Mode = GPIO_MODE_IT_RISING_FALLING;
  GPIO_InitStruct.Pull = GPIO_PULLUP;
  HAL_GPIO_Init(E_STOP_GPIO_Port, &GPIO_InitStruct);

  /*Configure GPIO pins : M2_NOCTW_Pin M2_NFAULT_Pin AUX_INT_Pin */
  GPIO_InitStruct.Pin = M2_NOCTW_Pin|M2_NFAULT_Pin|AUX_INT_Pin;
  GPIO_InitStruct.Mode = GPIO_MODE_IT_RISING;
  GPIO_InitStruct.Pull = GPIO_NOPULL;
  HAL_GPIO_Init(GPIOB, &GPIO_InitStruct);

  /*Configure GPIO pins : M1_NOCTW_Pin M1_NFAULT_Pin ADC1_DRDY_Pin ADC2_DRDY_Pin */
  GPIO_InitStruct.Pin = M1_NOCTW_Pin|M1_NFAULT_Pin|ADC1_DRDY_Pin|ADC2_DRDY_Pin;
  GPIO_InitStruct.Mode = GPIO_MODE_IT_RISING;
  GPIO_InitStruct.Pull = GPIO_NOPULL;
  HAL_GPIO_Init(GPIOD, &GPIO_InitStruct);

  /*Configure GPIO pin : PROBE_OUT_Pin */
  GPIO_InitStruct.Pin = PROBE_OUT_Pin;
  GPIO_InitStruct.Mode = GPIO_MODE_OUTPUT_PP;
  GPIO_InitStruct.Pull = GPIO_NOPULL;
  GPIO_InitStruct.Speed = GPIO_SPEED_FREQ_MEDIUM;
  HAL_GPIO_Init(PROBE_OUT_GPIO_Port, &GPIO_InitStruct);

  /* EXTI interrupt init*/
  HAL_NVIC_SetPriority(E_STOP_EXTI_IRQn, 0, 0);
  HAL_NVIC_EnableIRQ(E_STOP_EXTI_IRQn);

  HAL_NVIC_SetPriority(ADC1_DRDY_EXTI_IRQn, 1, 0);
  HAL_NVIC_EnableIRQ(ADC1_DRDY_EXTI_IRQn);

}

 /* MPU Configuration */

void MPU_Config(void)
{
  MPU_Region_InitTypeDef MPU_InitStruct = {0};

  /* Disables the MPU */
  HAL_MPU_Disable();

  /** Initializes and configures the Region and the memory to be protected
  */
  MPU_InitStruct.Enable = MPU_REGION_ENABLE;
  MPU_InitStruct.Number = MPU_REGION_NUMBER0;
  MPU_InitStruct.BaseAddress = 0x0;
  MPU_InitStruct.Size = MPU_REGION_SIZE_4GB;
  MPU_InitStruct.SubRegionDisable = 0x87;
  MPU_InitStruct.TypeExtField = MPU_TEX_LEVEL0;
  MPU_InitStruct.AccessPermission = MPU_REGION_NO_ACCESS;
  MPU_InitStruct.DisableExec = MPU_INSTRUCTION_ACCESS_DISABLE;
  MPU_InitStruct.IsShareable = MPU_ACCESS_SHAREABLE;
  MPU_InitStruct.IsCacheable = MPU_ACCESS_NOT_CACHEABLE;
  MPU_InitStruct.IsBufferable = MPU_ACCESS_NOT_BUFFERABLE;

  HAL_MPU_ConfigRegion(&MPU_InitStruct);
  /* Enables the MPU */
  HAL_MPU_Enable(MPU_PRIVILEGED_DEFAULT);

}

void Error_Handler(void)
{
  __disable_irq();
  while (1)
  {
  }
}
